VERSION "..\..\trunk\components\winTestMT\code\canApi\dbcFiles\canBus_08.dbc, created by Octave and generateRandomDbc.m on 21-Feb-2017"

NS_ :

BS_:

BU_: ECU

BO_ 1249 frame_1249: 5 Vector__XXX
  SG_ checksum_17_8 : 23|8@0+ (1.0,0.0) [0.0|255.0] "" ECU
  SG_ sig_0_16 : 0|16@1- (1.0000000000000007E-7,0.0031622776601683794) [-1.1452233983162306E-4|0.006438877660168382] "km/h" ECU
  SG_ sig_27_9 : 27|9@0- (1.0,0.0) [-256.0|254.0] "" ECU
  SG_ sig_28_6 : 28|6@1- (10.0,0.0) [-320.0|300.0] "km/h" ECU
  SG_ sig_34_1 : 34|1@0+ (1.0,0.0) [0.0|1.0] "" ECU

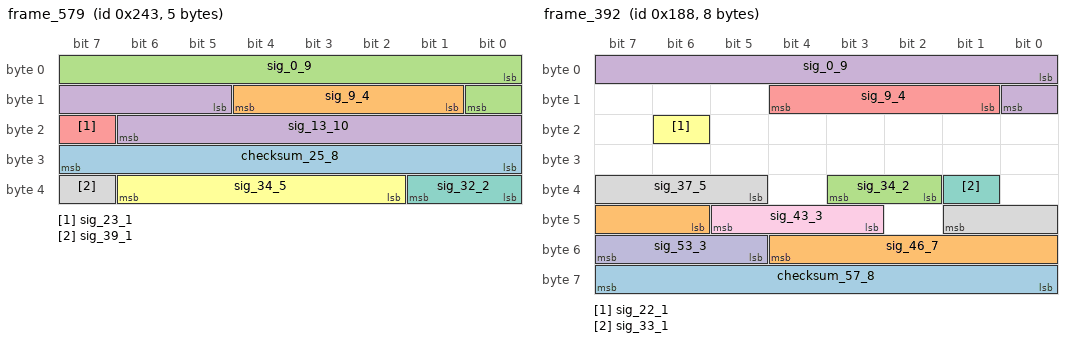
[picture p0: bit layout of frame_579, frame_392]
BO_ 579 frame_579: 5 Vector__XXX
  SG_ checksum_25_8 : 24|8@1+ (1.0,0.0) [0.0|255.0] "" ECU
  SG_ sig_9_4 : 9|4@1- (1.0,0.0) [-8.0|6.0] "" ECU
  SG_ sig_0_9 : 0|9@1+ (1.0,0.0) [0.0|510.0] "" ECU
  SG_ sig_13_10 : 13|10@1+ (1.0,0.0) [0.0|1022.0] "" ECU
  SG_ sig_23_1 : 23|1@1+ (1.0,0.0) [0.0|1.0] "" ECU
  SG_ sig_34_5 : 34|5@1- (0.0010000000000000002,-0.03162277660168379) [-0.04762277660168379|-0.017622776601683786] "W" ECU
  SG_ sig_32_2 : 32|2@1+ (1.0,0.0) [0.0|3.0] "" ECU
  SG_ sig_39_1 : 39|1@1+ (1.0,0.0) [0.0|1.0] "" ECU

BO_ 392 frame_392: 8 ECU
  SG_ checksum_57_8 : 56|8@1+ (1.0,0.0) [0.0|255.0] "" Vector__XXX
  SG_ sig_46_7 : 46|7@1+ (0.1,-3.1622776601683795) [-3.1622776601683795|9.437722339831621] "kWh" Vector__XXX
  SG_ sig_34_2 : 34|2@1+ (1.0,0.0) [0.0|3.0] "" Vector__XXX
  SG_ sig_0_9 : 0|9@1- (0.010000000000000002,3.1622776601683795) [0.602277660168379|5.70227766016838] "kWh" Vector__XXX
  SG_ sig_9_4 : 9|4@1- (0.1,-0.31622776601683794) [-1.116227766016838|0.28377223398316215] "kWh" Vector__XXX
  SG_ sig_22_1 : 22|1@1+ (1.0,0.0) [0.0|1.0] "" Vector__XXX
  SG_ sig_33_1 : 33|1@1+ (1.0,0.0) [0.0|1.0] "" Vector__XXX
  SG_ sig_37_5 : 37|5@1+ (0.010000000000000002,0.31622776601683794) [0.31622776601683794|0.616227766016838] "kWh" Vector__XXX
  SG_ sig_43_3 : 43|3@1- (1.0,0.0) [-4.0|2.0] "" Vector__XXX
  SG_ sig_53_3 : 53|3@1- (1.0,0.0) [-4.0|2.0] "" Vector__XXX

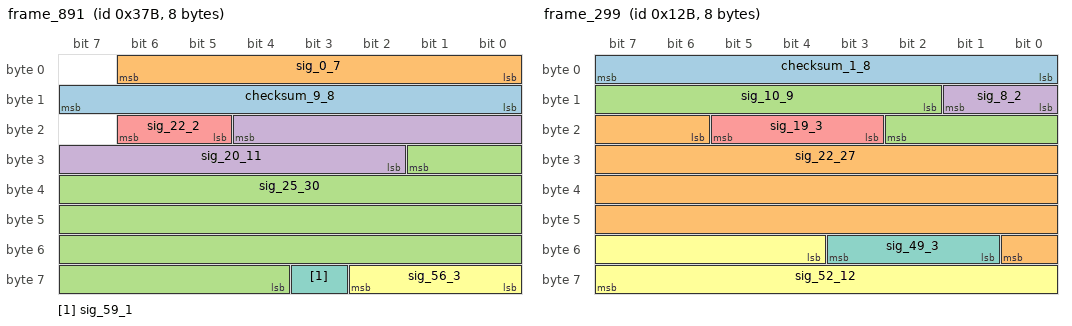
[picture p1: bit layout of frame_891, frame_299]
BO_ 891 frame_891: 8 Vector__XXX
  SG_ checksum_9_8 : 8|8@1+ (1.0,0.0) [0.0|255.0] "" ECU
  SG_ sig_0_7 : 0|7@1+ (10.0,0.0) [0.0|1260.0] "A" ECU
  SG_ sig_25_30 : 25|30@0+ (1.0000000000000014E-13,3.1622776601683795E-5) [3.1622776601683795E-5|1.3899695880168394E-4] "s" ECU
  SG_ sig_20_11 : 20|11@0- (1.0,0.0) [-1024.0|1022.0] "" ECU
  SG_ sig_22_2 : 22|2@0- (1.0,0.0) [-2.0|1.0] "" ECU
  SG_ sig_56_3 : 56|3@1+ (1.0,0.0) [0.0|6.0] "" ECU
  SG_ sig_59_1 : 59|1@0+ (1.0,0.0) [0.0|1.0] "" ECU

BO_ 1082 frame_1082: 6 Vector__XXX
  SG_ checksum_1_8 : 0|8@1+ (1.0,0.0) [0.0|255.0] "" ECU
  SG_ sig_38_12 : 38|12@0- (1.0,0.0) [-2048.0|2046.0] "" ECU
  SG_ sig_10_11 : 10|11@1- (10.0,0.0) [-10240.0|10220.0] "W" ECU
  SG_ sig_22_8 : 22|8@1+ (1.0,0.0) [0.0|254.0] "" ECU
  SG_ sig_39_4 : 39|4@1- (1.0,0.0) [-8.0|6.0] "V" ECU

BO_ 878 frame_878: 5 Vector__XXX
  SG_ checksum_17_8 : 23|8@0+ (1.0,0.0) [0.0|255.0] "" ECU
  SG_ sig_7_16 : 7|16@0+ (0.0010000000000000002,-31.622776601683793) [-31.622776601683793|33.911223398316224] "m/s^2" ECU
  SG_ sig_24_13 : 24|13@1- (1.0,0.0) [-4096.0|4094.0] "" ECU
  SG_ sig_39_2 : 39|2@0+ (1.0,0.0) [0.0|3.0] "" ECU

BO_ 299 frame_299: 8 Vector__XXX
  SG_ checksum_1_8 : 0|8@1+ (1.0,0.0) [0.0|255.0] "" ECU
  SG_ sig_22_27 : 22|27@1+ (1.0000000000000014E-12,3.1622776601683795E-5) [3.1622776601683795E-5|1.6584050260168398E-4] "V" ECU
  SG_ sig_10_9 : 10|9@1- (1.0,0.0) [-256.0|254.0] "" ECU
  SG_ sig_8_2 : 8|2@1+ (1.0,0.0) [0.0|3.0] "" ECU
  SG_ sig_19_3 : 19|3@1+ (1.0,0.0) [0.0|6.0] "" ECU
  SG_ sig_52_12 : 52|12@1+ (1.0,0.0) [0.0|4094.0] "" ECU
  SG_ sig_49_3 : 49|3@1- (1.0,0.0) [-4.0|2.0] "" ECU

BO_ 1921 frame_1921: 2 Vector__XXX
  SG_ checksum_1_8 : 0|8@1+ (1.0,0.0) [0.0|255.0] "" ECU
  SG_ sig_9_7 : 9|7@1+ (1.0,31.622776601683793) [31.622776601683793|157.6227766016838] "W" ECU
  SG_ sig_8_1 : 8|1@1+ (1.0,0.0) [0.0|1.0] "" ECU

BO_ 754 frame_754: 4 Vector__XXX
  SG_ checksum_9_8 : 15|8@0+ (1.0,0.0) [0.0|255.0] "" ECU
  SG_ sig_5_6 : 5|6@0- (1.0,0.0) [-32.0|30.0] "" ECU
  SG_ sig_7_2 : 7|2@0+ (1.0,0.0) [0.0|3.0] "" ECU
  SG_ sig_20_13 : 20|13@0- (10.0,-31622.776601683792) [-72582.77660168378|9317.223398316208] "s" ECU

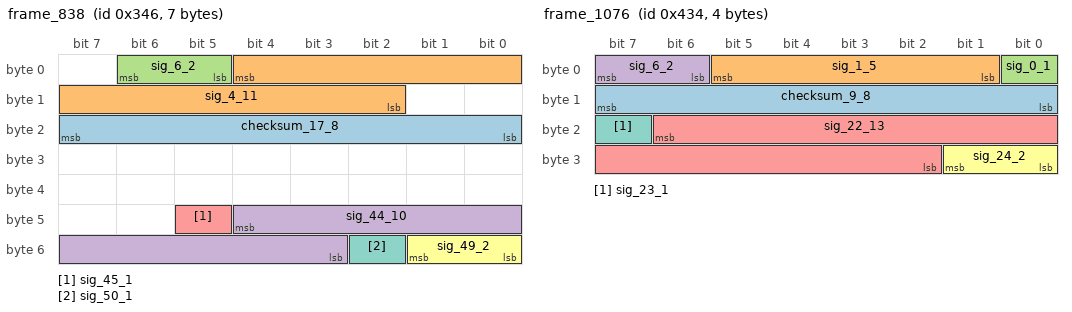
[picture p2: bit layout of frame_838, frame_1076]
BO_ 838 frame_838: 7 Vector__XXX
  SG_ checksum_17_8 : 23|8@0+ (1.0,0.0) [0.0|255.0] "" ECU
  SG_ sig_4_11 : 4|11@0+ (1.0000000000000008E-8,-3.162277660168379E-6) [-3.162277660168379E-6|1.729772233983164E-5] "A" ECU
  SG_ sig_6_2 : 6|2@0+ (1.0,0.0) [0.0|3.0] "" ECU
  SG_ sig_44_10 : 44|10@0- (1.0,0.0) [-512.0|510.0] "" ECU
  SG_ sig_45_1 : 45|1@0+ (1.0,0.0) [0.0|1.0] "" ECU
  SG_ sig_49_2 : 49|2@0- (1.0,0.0) [-2.0|1.0] "" ECU
  SG_ sig_50_1 : 50|1@0+ (1.0,0.0) [0.0|1.0] "" ECU

BO_ 33 frame_33: 4 ECU
  SG_ checksum_9_8 : 15|8@0+ (1.0,0.0) [0.0|255.0] "" Vector__XXX
  SG_ sig_7_8 : 7|8@0+ (1.0000000000000006E-5,0.0) [0.0|0.0025400000000000015] "km/h" Vector__XXX
  SG_ sig_21_11 : 21|11@0- (0.1,-31.622776601683793) [-134.0227766016838|70.5772233983162] "A" Vector__XXX
  SG_ sig_23_2 : 23|2@0- (1.0,0.0) [-2.0|1.0] "" Vector__XXX
  SG_ sig_26_3 : 26|3@0+ (1.0,0.0) [0.0|6.0] "" Vector__XXX

BO_ 1076 frame_1076: 4 ECU
  SG_ checksum_9_8 : 8|8@1+ (1.0,0.0) [0.0|255.0] "" Vector__XXX
  SG_ sig_1_5 : 1|5@1+ (1.0,0.0) [0.0|30.0] "" Vector__XXX
  SG_ sig_0_1 : 0|1@1+ (1.0,0.0) [0.0|1.0] "" Vector__XXX
  SG_ sig_6_2 : 6|2@1+ (1.0,0.0) [0.0|3.0] "" Vector__XXX
  SG_ sig_22_13 : 22|13@0+ (1.0,0.0) [0.0|8190.0] "" Vector__XXX
  SG_ sig_24_2 : 24|2@1+ (1.0,0.0) [0.0|3.0] "" Vector__XXX
  SG_ sig_23_1 : 23|1@1+ (1.0,0.0) [0.0|1.0] "" Vector__XXX

BO_ 16 frame_16: 7 Vector__XXX
  SG_ checksum_17_8 : 23|8@0+ (1.0,0.0) [0.0|255.0] "" ECU
  SG_ sig_0_13 : 0|13@1- (10.0,0.0) [-40960.0|40940.0] "s" ECU
  SG_ sig_13_3 : 13|3@1- (1.0,0.0) [-4.0|2.0] "" ECU
  SG_ sig_29_26 : 29|26@0+ (0.0010000000000000002,-31622.776601683792) [-31622.776601683792|35486.08539831623] "kWh" ECU
  SG_ sig_30_1 : 30|1@0+ (1.0,0.0) [0.0|1.0] "" ECU
  SG_ sig_51_4 : 51|4@0+ (10000.0,31622.776601683792) [31622.776601683792|171622.77660168378] "kWh" ECU

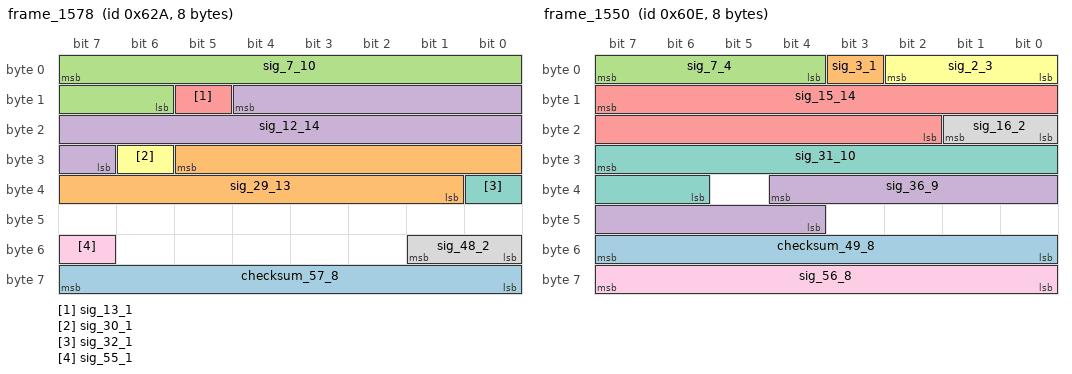
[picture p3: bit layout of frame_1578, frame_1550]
BO_ 1578 frame_1578: 8 Vector__XXX
  SG_ checksum_57_8 : 63|8@0+ (1.0,0.0) [0.0|255.0] "" ECU
  SG_ sig_29_13 : 29|13@0- (0.1,0.0) [-409.6|409.40000000000003] "A" ECU
  SG_ sig_7_10 : 7|10@0- (1.0,0.0) [-512.0|510.0] "" ECU
  SG_ sig_12_14 : 12|14@0+ (0.1,0.0) [0.0|1638.2] "W" ECU
  SG_ sig_13_1 : 13|1@0+ (1.0,0.0) [0.0|1.0] "" ECU
  SG_ sig_30_1 : 30|1@0+ (1.0,0.0) [0.0|1.0] "" ECU
  SG_ sig_32_1 : 32|1@1+ (1.0,0.0) [0.0|1.0] "" ECU
  SG_ sig_48_2 : 48|2@1+ (1.0,0.0) [0.0|3.0] "" ECU
  SG_ sig_55_1 : 55|1@0+ (1.0,0.0) [0.0|1.0] "" ECU

BO_ 1550 frame_1550: 8 Vector__XXX
  SG_ checksum_49_8 : 48|8@1+ (1.0,0.0) [0.0|255.0] "" ECU
  SG_ sig_3_1 : 3|1@1+ (1.0,0.0) [0.0|1.0] "" ECU
  SG_ sig_7_4 : 7|4@0+ (100.0,316.22776601683796) [316.22776601683796|1716.227766016838] "V" ECU
  SG_ sig_36_9 : 36|9@0- (1.0000000000000005E-4,0.03162277660168379) [0.00602277660168378|0.057022776601683804] "A" ECU
  SG_ sig_15_14 : 15|14@0- (1.0,0.0) [-8192.0|8190.0] "" ECU
  SG_ sig_2_3 : 2|3@0+ (1.0,0.0) [0.0|6.0] "" ECU
  SG_ sig_31_10 : 31|10@0- (0.0010000000000000002,0.0) [-0.5120000000000001|0.5100000000000001] "W" ECU
  SG_ sig_16_2 : 16|2@1- (1.0,0.0) [-2.0|1.0] "" ECU
  SG_ sig_56_8 : 56|8@1- (1.0,0.0) [-128.0|126.0] "" ECU

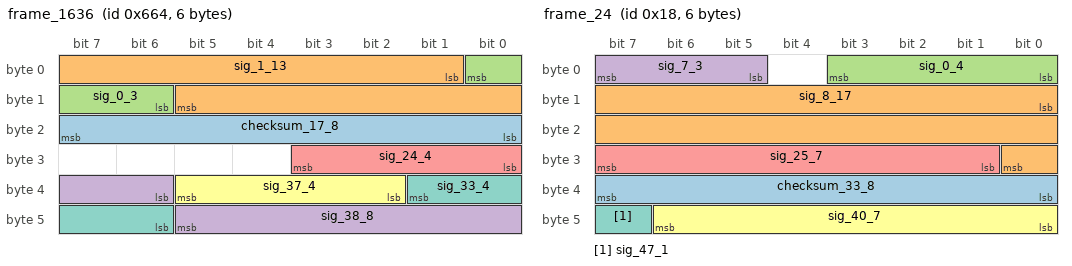
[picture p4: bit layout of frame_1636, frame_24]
BO_ 1636 frame_1636: 6 Vector__XXX
  SG_ checksum_17_8 : 23|8@0+ (1.0,0.0) [0.0|255.0] "" ECU
  SG_ sig_1_13 : 1|13@1- (1.0000000000000005E-4,-0.31622776601683794) [-0.7258277660168382|0.09317223398316227] "km/h" ECU
  SG_ sig_0_3 : 0|3@0+ (1.0,0.0) [0.0|6.0] "" ECU
  SG_ sig_38_8 : 38|8@1- (1000.0,0.0) [-128000.0|126000.0] "V" ECU
  SG_ sig_24_4 : 24|4@1- (1.0000000000000006E-6,3.162277660168379E-6) [-4.8377223398316255E-6|9.162277660168383E-6] "m/s^2" ECU
  SG_ sig_37_4 : 37|4@0+ (0.1,0.0) [0.0|1.4000000000000001] "W" ECU
  SG_ sig_33_4 : 33|4@0- (1.0,0.0) [-8.0|6.0] "" ECU

BO_ 24 frame_24: 6 ECU
  SG_ checksum_33_8 : 32|8@1+ (1.0,0.0) [0.0|255.0] "" Vector__XXX
  SG_ sig_8_17 : 8|17@1+ (1.0,0.0) [0.0|131070.0] "" Vector__XXX
  SG_ sig_0_4 : 0|4@1- (1.0,-3.1622776601683795) [-11.16227766016838|2.8377223398316205] "kWh" Vector__XXX
  SG_ sig_7_3 : 7|3@0+ (1.0,0.0) [0.0|6.0] "" Vector__XXX
  SG_ sig_25_7 : 25|7@1- (0.010000000000000002,-0.31622776601683794) [-0.9562277660168381|0.30377223398316217] "V" Vector__XXX
  SG_ sig_40_7 : 40|7@1+ (1.0,0.0) [0.0|126.0] "" Vector__XXX
  SG_ sig_47_1 : 47|1@1+ (1.0,0.0) [0.0|1.0] "" Vector__XXX

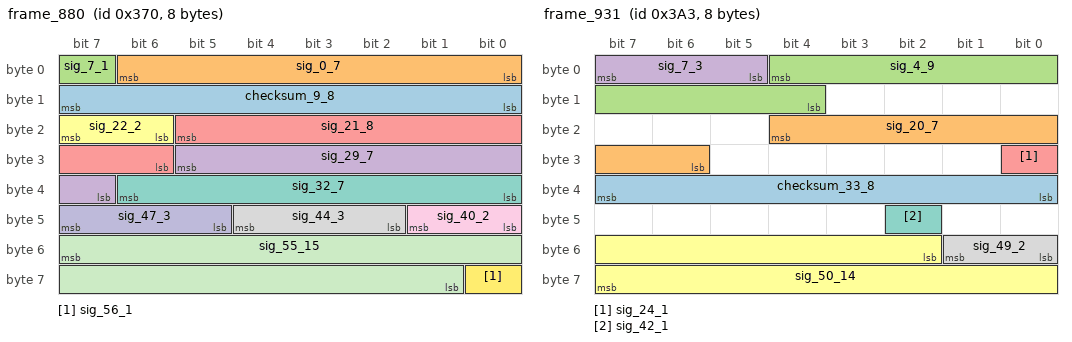
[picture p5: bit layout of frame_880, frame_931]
BO_ 880 frame_880: 8 ECU
  SG_ checksum_9_8 : 8|8@1+ (1.0,0.0) [0.0|255.0] "" Vector__XXX
  SG_ sig_0_7 : 0|7@1- (1.0,0.0) [-64.0|62.0] "" Vector__XXX
  SG_ sig_7_1 : 7|1@0+ (1.0,0.0) [0.0|1.0] "" Vector__XXX
  SG_ sig_29_7 : 29|7@0- (1.0,0.0) [-64.0|62.0] "" Vector__XXX
  SG_ sig_21_8 : 21|8@0- (100.0,0.0) [-12800.0|12600.0] "kWh" Vector__XXX
  SG_ sig_22_2 : 22|2@1- (1.0,0.0) [-2.0|1.0] "" Vector__XXX
  SG_ sig_32_7 : 32|7@1+ (0.0010000000000000002,0.0) [0.0|0.12600000000000003] "A" Vector__XXX
  SG_ sig_44_3 : 44|3@0- (1.0,0.0) [-4.0|2.0] "" Vector__XXX
  SG_ sig_40_2 : 40|2@1- (1.0,0.0) [-2.0|1.0] "" Vector__XXX
  SG_ sig_47_3 : 47|3@0+ (1.0,0.0) [0.0|6.0] "" Vector__XXX
  SG_ sig_55_15 : 55|15@0- (0.1,0.0) [-1638.4|1638.2] "m/s^2" Vector__XXX
  SG_ sig_56_1 : 56|1@0+ (1.0,0.0) [0.0|1.0] "" Vector__XXX

BO_ 575 frame_575: 4 Vector__XXX
  SG_ checksum_1_8 : 7|8@0+ (1.0,0.0) [0.0|255.0] "" ECU
  SG_ sig_8_8 : 8|8@0+ (1.0000000000000007E-7,3.162277660168379E-6) [3.162277660168379E-6|2.85622776601684E-5] "V" ECU
  SG_ sig_14_6 : 14|6@0- (1.0000000000000007E-7,3.162277660168379E-6) [-3.7722339831623205E-8|6.162277660168381E-6] "W" ECU
  SG_ sig_15_1 : 15|1@0+ (1.0,0.0) [0.0|1.0] "" ECU
  SG_ sig_16_6 : 16|6@0+ (0.0010000000000000002,0.0) [0.0|0.06200000000000001] "km/h" ECU
  SG_ sig_26_3 : 26|3@0- (1.0,0.0) [-4.0|2.0] "" ECU

BO_ 931 frame_931: 8 Vector__XXX
  SG_ checksum_33_8 : 39|8@0+ (1.0,0.0) [0.0|255.0] "" ECU
  SG_ sig_20_7 : 20|7@0- (10.0,316.22776601683796) [-323.77223398316204|936.2277660168379] "W" ECU
  SG_ sig_4_9 : 4|9@0+ (1.0,0.0) [0.0|510.0] "" ECU
  SG_ sig_7_3 : 7|3@0+ (1.0,0.0) [0.0|6.0] "" ECU
  SG_ sig_24_1 : 24|1@1+ (1.0,0.0) [0.0|1.0] "" ECU
  SG_ sig_50_14 : 50|14@1+ (1.0000000000000009E-9,3.162277660168379E-6) [3.162277660168379E-6|1.954427766016839E-5] "kWh" ECU
  SG_ sig_42_1 : 42|1@0+ (1.0,0.0) [0.0|1.0] "" ECU
  SG_ sig_49_2 : 49|2@0- (1.0,0.0) [-2.0|1.0] "" ECU

BO_ 525 frame_525: 7 Vector__XXX
  SG_ checksum_9_8 : 8|8@1+ (1.0,0.0) [0.0|255.0] "" ECU
  SG_ sig_0_8 : 0|8@1- (1.0000000000000006E-6,-3.1622776601683795E-5) [-1.5962277660168386E-4|9.437722339831629E-5] "kWh" ECU
  SG_ sig_42_1 : 42|1@1+ (1.0,0.0) [0.0|1.0] "" ECU
  SG_ sig_20_11 : 20|11@1- (1.0,0.0) [-1024.0|1022.0] "" ECU
  SG_ sig_17_3 : 17|3@1+ (1.0,0.0) [0.0|6.0] "" ECU
  SG_ sig_31_9 : 31|9@1+ (1.0000000000000008E-8,0.0) [0.0|5.1000000000000045E-6] "kWh" ECU
  SG_ sig_47_9 : 47|9@1- (1.0,0.0) [-256.0|254.0] "kWh" ECU

BO_ 1645 frame_1645: 3 Vector__XXX
  SG_ checksum_9_8 : 15|8@0+ (1.0,0.0) [0.0|255.0] "" ECU
  SG_ sig_5_6 : 5|6@0+ (100.0,0.0) [0.0|6200.0] "W" ECU
  SG_ sig_7_2 : 7|2@0+ (1.0,0.0) [0.0|3.0] "" ECU
  SG_ sig_23_8 : 23|8@0+ (100.0,3162.2776601683795) [3162.2776601683795|28562.27766016838] "W" ECU

BO_ 646 frame_646: 5 ECU
  SG_ checksum_17_8 : 23|8@0+ (1.0,0.0) [0.0|255.0] "" Vector__XXX
  SG_ sig_6_5 : 6|5@0+ (1.0,0.0) [0.0|30.0] "" Vector__XXX
  SG_ sig_0_2 : 0|2@1+ (1.0,0.0) [0.0|3.0] "" Vector__XXX
  SG_ sig_7_8 : 7|8@1- (1.0,0.0) [-128.0|126.0] "" Vector__XXX
  SG_ sig_15_1 : 15|1@0+ (1.0,0.0) [0.0|1.0] "" Vector__XXX
  SG_ sig_29_14 : 29|14@0- (1.0000000000000006E-5,0.0) [-0.08192000000000005|0.08190000000000004] "m/s^2" Vector__XXX
  SG_ sig_30_2 : 30|2@1+ (1.0,0.0) [0.0|3.0] "" Vector__XXX

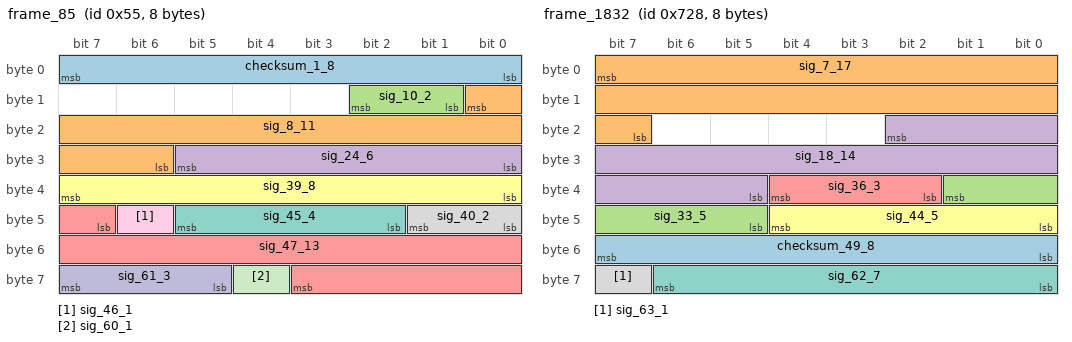
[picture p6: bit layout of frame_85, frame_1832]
BO_ 85 frame_85: 8 ECU
  SG_ checksum_1_8 : 0|8@1+ (1.0,0.0) [0.0|255.0] "" Vector__XXX
  SG_ sig_8_11 : 8|11@0- (1.0000000000000006E-6,-3.1622776601683794E-4) [-0.0013402277660168385|7.057722339831626E-4] "kWh" Vector__XXX
  SG_ sig_10_2 : 10|2@0+ (1.0,0.0) [0.0|3.0] "" Vector__XXX
  SG_ sig_24_6 : 24|6@1+ (1.0,31.622776601683793) [31.622776601683793|93.6227766016838] "V" Vector__XXX
  SG_ sig_47_13 : 47|13@1- (1.0,0.0) [-4096.0|4094.0] "" Vector__XXX
  SG_ sig_39_8 : 39|8@0- (0.010000000000000002,0.31622776601683794) [-0.9637722339831623|1.5762277660168382] "m/s^2" Vector__XXX
  SG_ sig_45_4 : 45|4@0- (10000.0,-31622.776601683792) [-111622.77660168378|28377.223398316208] "s" Vector__XXX
  SG_ sig_40_2 : 40|2@1- (1.0,0.0) [-2.0|1.0] "" Vector__XXX
  SG_ sig_46_1 : 46|1@0+ (1.0,0.0) [0.0|1.0] "" Vector__XXX
  SG_ sig_61_3 : 61|3@1- (1.0,0.0) [-4.0|2.0] "" Vector__XXX
  SG_ sig_60_1 : 60|1@1+ (1.0,0.0) [0.0|1.0] "" Vector__XXX

BO_ 1832 frame_1832: 8 Vector__XXX
  SG_ checksum_49_8 : 55|8@0+ (1.0,0.0) [0.0|255.0] "" ECU
  SG_ sig_7_17 : 7|17@0- (1.0,0.0) [-65536.0|65534.0] "" ECU
  SG_ sig_33_5 : 33|5@0- (1000.0,0.0) [-16000.0|14000.0] "m/s^2" ECU
  SG_ sig_18_14 : 18|14@0- (1.0000000000000009E-9,3.162277660168379E-6) [-5.029722339831628E-6|1.1352277660168387E-5] "km/h" ECU
  SG_ sig_36_3 : 36|3@0+ (1.0,0.0) [0.0|6.0] "" ECU
  SG_ sig_44_5 : 44|5@0- (1.0000000000000006E-6,3.1622776601683795E-5) [1.5622776601683786E-5|4.5622776601683804E-5] "km/h" ECU
  SG_ sig_62_7 : 62|7@0+ (0.010000000000000002,0.0) [0.0|1.2600000000000002] "m/s^2" ECU
  SG_ sig_63_1 : 63|1@0+ (1.0,0.0) [0.0|1.0] "" ECU

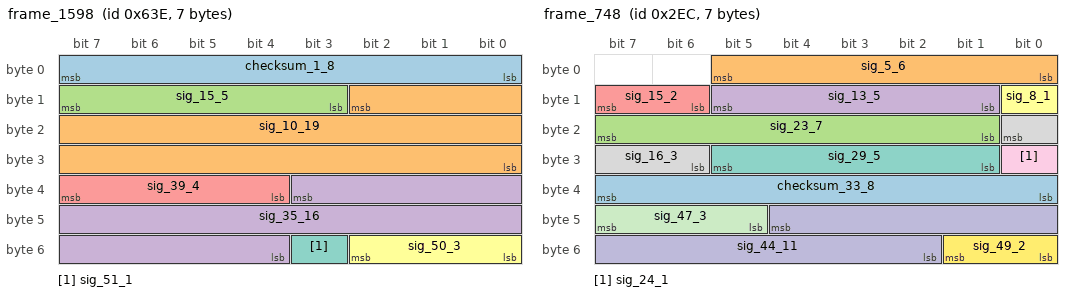
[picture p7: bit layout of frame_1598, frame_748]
BO_ 1598 frame_1598: 7 Vector__XXX
  SG_ checksum_1_8 : 7|8@0+ (1.0,0.0) [0.0|255.0] "" ECU
  SG_ sig_10_19 : 10|19@0+ (0.1,0.0) [0.0|52428.600000000006] "km/h" ECU
  SG_ sig_15_5 : 15|5@0- (10.0,-316.22776601683796) [-476.22776601683796|-176.22776601683796] "A" ECU
  SG_ sig_35_16 : 35|16@0- (1.0000000000000007E-7,0.0) [-0.0032768000000000025|0.0032766000000000023] "m/s^2" ECU
  SG_ sig_39_4 : 39|4@0- (1000.0,-3162.2776601683795) [-11162.27766016838|2837.7223398316205] "m/s^2" ECU
  SG_ sig_50_3 : 50|3@0+ (1.0,0.0) [0.0|6.0] "" ECU
  SG_ sig_51_1 : 51|1@0+ (1.0,0.0) [0.0|1.0] "" ECU

BO_ 696 frame_696: 3 ECU
  SG_ checksum_1_8 : 0|8@1+ (1.0,0.0) [0.0|255.0] "" Vector__XXX
  SG_ sig_11_13 : 11|13@1+ (1.0000000000000009E-9,-3.162277660168379E-6) [-3.162277660168379E-6|5.027722339831629E-6] "kWh" Vector__XXX
  SG_ sig_8_2 : 8|2@1- (1.0,0.0) [-2.0|1.0] "" Vector__XXX
  SG_ sig_10_1 : 10|1@1+ (1.0,0.0) [0.0|1.0] "" Vector__XXX

BO_ 1933 frame_1933: 5 Vector__XXX
  SG_ checksum_9_8 : 8|8@1+ (1.0,0.0) [0.0|255.0] "" ECU
  SG_ sig_1_6 : 1|6@1- (1.0000000000000007E-7,3.162277660168379E-6) [-3.7722339831623205E-8|6.162277660168381E-6] "A" ECU
  SG_ sig_7_1 : 7|1@1+ (1.0,0.0) [0.0|1.0] "" ECU
  SG_ sig_18_15 : 18|15@1- (1.0000000000000006E-5,0.0) [-0.1638400000000001|0.1638200000000001] "V" ECU
  SG_ sig_39_7 : 39|7@0+ (1.0,0.0) [0.0|126.0] "" ECU

BO_ 991 frame_991: 5 ECU
  SG_ checksum_1_8 : 0|8@1+ (1.0,0.0) [0.0|255.0] "" Vector__XXX
  SG_ sig_23_23 : 23|23@0+ (1.0000000000000005E-4,0.0) [0.0|838.8606000000004] "s" Vector__XXX
  SG_ sig_15_8 : 15|8@0- (1.0000000000000007E-7,3.162277660168379E-6) [-9.63772233983163E-6|1.576227766016839E-5] "m/s^2" Vector__XXX
  SG_ sig_32_1 : 32|1@1+ (1.0,0.0) [0.0|1.0] "" Vector__XXX

BO_ 1959 frame_1959: 3 Vector__XXX
  SG_ checksum_1_8 : 0|8@1+ (1.0,0.0) [0.0|255.0] "" ECU
  SG_ sig_8_16 : 8|16@1- (1.0,0.0) [-32768.0|32766.0] "" ECU

BO_ 748 frame_748: 7 Vector__XXX
  SG_ checksum_33_8 : 39|8@0+ (1.0,0.0) [0.0|255.0] "" ECU
  SG_ sig_5_6 : 5|6@0- (0.1,3.1622776601683795) [-0.037722339831620655|6.16227766016838] "kWh" ECU
  SG_ sig_23_7 : 23|7@0+ (1.0,0.0) [0.0|126.0] "" ECU
  SG_ sig_13_5 : 13|5@0+ (1.0,0.0) [0.0|30.0] "" ECU
  SG_ sig_15_2 : 15|2@0+ (1.0,0.0) [0.0|3.0] "" ECU
  SG_ sig_8_1 : 8|1@0+ (1.0,0.0) [0.0|1.0] "" ECU
  SG_ sig_29_5 : 29|5@0- (1.0,31.622776601683793) [15.622776601683793|45.622776601683796] "A" ECU
  SG_ sig_16_3 : 16|3@0+ (1.0,0.0) [0.0|6.0] "" ECU
  SG_ sig_24_1 : 24|1@0+ (1.0,0.0) [0.0|1.0] "" ECU
  SG_ sig_44_11 : 44|11@0+ (0.1,31.622776601683793) [31.622776601683793|236.22277660168382] "km/h" ECU
  SG_ sig_47_3 : 47|3@0- (1.0,0.0) [-4.0|2.0] "" ECU
  SG_ sig_49_2 : 49|2@0+ (1.0,0.0) [0.0|3.0] "" ECU

BO_ 1566 frame_1566: 5 Vector__XXX
  SG_ checksum_17_8 : 23|8@0+ (1.0,0.0) [0.0|255.0] "" ECU
  SG_ sig_2_12 : 2|12@1+ (1.0000000000000006E-6,0.0031622776601683794) [0.0031622776601683794|0.007256277660168382] "km/h" ECU
  SG_ sig_1_1 : 1|1@1+ (1.0,0.0) [0.0|1.0] "" ECU
  SG_ sig_0_3 : 0|3@0+ (1.0,0.0) [0.0|6.0] "" ECU
  SG_ sig_29_9 : 29|9@1- (0.0010000000000000002,0.0) [-0.25600000000000006|0.25400000000000006] "s" ECU
  SG_ sig_28_7 : 28|7@0- (1.0000000000000006E-5,3.1622776601683794E-4) [-3.2377223398316244E-4|9.362277660168383E-4] "V" ECU

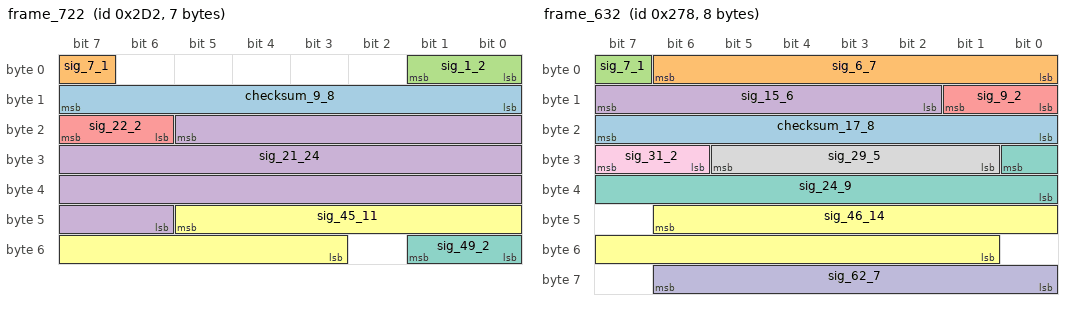
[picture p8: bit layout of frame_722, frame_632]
BO_ 722 frame_722: 7 Vector__XXX
  SG_ checksum_9_8 : 15|8@0+ (1.0,0.0) [0.0|255.0] "" ECU
  SG_ sig_7_1 : 7|1@0+ (1.0,0.0) [0.0|1.0] "" ECU
  SG_ sig_1_2 : 1|2@0- (1.0,0.0) [-2.0|1.0] "" ECU
  SG_ sig_21_24 : 21|24@0- (1.0000000000000011E-10,-3.1622776601683794E-4) [-0.0011550885660168387|5.22632833983163E-4] "A" ECU
  SG_ sig_22_2 : 22|2@1- (1.0,0.0) [-2.0|1.0] "" ECU
  SG_ sig_45_11 : 45|11@0+ (1.0,0.0) [0.0|2046.0] "" ECU
  SG_ sig_49_2 : 49|2@0+ (1.0,0.0) [0.0|3.0] "" ECU

BO_ 632 frame_632: 8 ECU
  SG_ checksum_17_8 : 23|8@0+ (1.0,0.0) [0.0|255.0] "" Vector__XXX
  SG_ sig_6_7 : 6|7@0+ (1000.0,-31622.776601683792) [-31622.776601683792|94377.22339831622] "m/s^2" Vector__XXX
  SG_ sig_7_1 : 7|1@0+ (1.0,0.0) [0.0|1.0] "" Vector__XXX
  SG_ sig_15_6 : 15|6@0- (1.0,0.0) [-32.0|30.0] "" Vector__XXX
  SG_ sig_9_2 : 9|2@0+ (1.0,0.0) [0.0|3.0] "" Vector__XXX
  SG_ sig_46_14 : 46|14@0+ (1.0000000000000005E-4,-0.31622776601683794) [-0.31622776601683794|1.3219722339831628] "A" Vector__XXX
  SG_ sig_24_9 : 24|9@0- (1.0,0.0) [-256.0|254.0] "" Vector__XXX
  SG_ sig_29_5 : 29|5@0- (1.0000000000000007E-7,3.162277660168379E-6) [1.562277660168378E-6|4.56227766016838E-6] "W" Vector__XXX
  SG_ sig_31_2 : 31|2@0+ (1.0,0.0) [0.0|3.0] "" Vector__XXX
  SG_ sig_62_7 : 62|7@0- (100.0,3162.2776601683795) [-3237.7223398316205|9362.27766016838] "km/h" Vector__XXX

BO_ 1388 frame_1388: 7 ECU
  SG_ checksum_1_8 : 7|8@0+ (1.0,0.0) [0.0|255.0] "" Vector__XXX
  SG_ sig_40_6 : 40|6@0- (0.010000000000000002,0.0) [-0.32000000000000006|0.30000000000000004] "s" Vector__XXX
  SG_ sig_14_15 : 14|15@0- (1.0000000000000007E-7,-0.0031622776601683794) [-0.004800677660168381|-0.001524077660168378] "km/h" Vector__XXX
  SG_ sig_15_1 : 15|1@0+ (1.0,0.0) [0.0|1.0] "" Vector__XXX
  SG_ sig_24_16 : 24|16@0+ (1.0,0.0) [0.0|65534.0] "" Vector__XXX
  SG_ sig_31_7 : 31|7@0+ (0.010000000000000002,0.31622776601683794) [0.31622776601683794|1.5762277660168382] "W" Vector__XXX
  SG_ sig_50_3 : 50|3@0- (1.0,0.0) [-4.0|2.0] "" Vector__XXX

BO_ 1817 frame_1817: 5 Vector__XXX
  SG_ checksum_9_8 : 15|8@0+ (1.0,0.0) [0.0|255.0] "" ECU
  SG_ sig_0_8 : 0|8@1- (1000.0,31622.776601683792) [-96377.22339831622|157622.77660168378] "V" ECU
  SG_ sig_22_21 : 22|21@0- (1.0000000000000009E-9,-3.1622776601683794E-4) [-0.0013648037660168389|7.32346233983163E-4] "W" ECU
  SG_ sig_23_1 : 23|1@0+ (1.0,0.0) [0.0|1.0] "" ECU
  SG_ sig_32_2 : 32|2@1+ (1.0,0.0) [0.0|3.0] "" ECU

BO_ 755 frame_755: 5 ECU
  SG_ checksum_25_8 : 31|8@0+ (1.0,0.0) [0.0|255.0] "" Vector__XXX
  SG_ sig_15_14 : 15|14@0- (1.0,0.0) [-8192.0|8190.0] "" Vector__XXX
  SG_ sig_0_8 : 0|8@1+ (1.0,-31.622776601683793) [-31.622776601683793|222.3772233983162] "km/h" Vector__XXX
  SG_ sig_17_1 : 17|1@0+ (1.0,0.0) [0.0|1.0] "" Vector__XXX
  SG_ sig_16_1 : 16|1@1+ (1.0,0.0) [0.0|1.0] "" Vector__XXX
  SG_ sig_36_4 : 36|4@1- (1.0,3.1622776601683795) [-4.83772233983162|9.16227766016838] "s" Vector__XXX
  SG_ sig_35_4 : 35|4@0+ (1.0000000000000006E-6,-3.162277660168379E-6) [-3.162277660168379E-6|1.0837722339831629E-5] "s" Vector__XXX

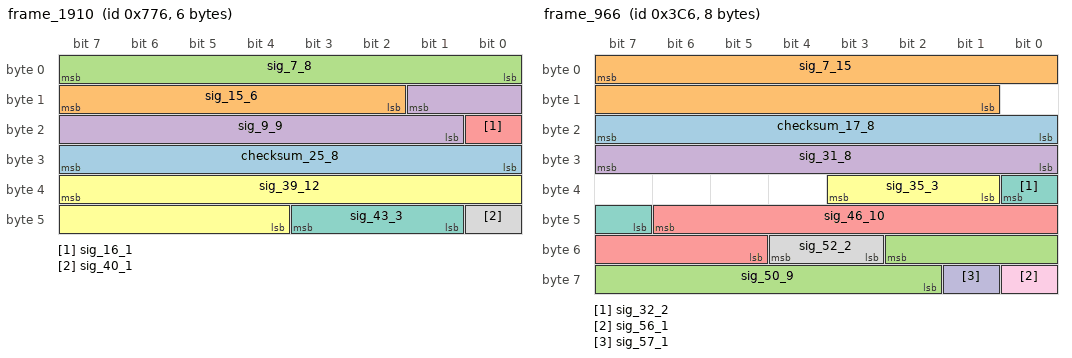
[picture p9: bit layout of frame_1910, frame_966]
BO_ 1910 frame_1910: 6 Vector__XXX
  SG_ checksum_25_8 : 31|8@0+ (1.0,0.0) [0.0|255.0] "" ECU
  SG_ sig_15_6 : 15|6@0- (1.0,0.0) [-32.0|30.0] "" ECU
  SG_ sig_7_8 : 7|8@0- (1.0,0.0) [-128.0|126.0] "" ECU
  SG_ sig_9_9 : 9|9@0+ (1.0000000000000006E-6,3.1622776601683794E-4) [3.1622776601683794E-4|8.262277660168382E-4] "W" ECU
  SG_ sig_16_1 : 16|1@0+ (1.0,0.0) [0.0|1.0] "" ECU
  SG_ sig_39_12 : 39|12@0- (1.0000000000000009E-9,-3.162277660168379E-6) [-5.210277660168381E-6|-1.1162776601683775E-6] "km/h" ECU
  SG_ sig_43_3 : 43|3@0- (1.0,0.0) [-4.0|2.0] "" ECU
  SG_ sig_40_1 : 40|1@0+ (1.0,0.0) [0.0|1.0] "" ECU

BO_ 966 frame_966: 8 ECU
  SG_ checksum_17_8 : 23|8@0+ (1.0,0.0) [0.0|255.0] "" Vector__XXX
  SG_ sig_7_15 : 7|15@0- (0.010000000000000002,0.0) [-163.84000000000003|163.82000000000002] "A" Vector__XXX
  SG_ sig_50_9 : 50|9@0+ (1.0,0.0) [0.0|510.0] "" Vector__XXX
  SG_ sig_31_8 : 31|8@0- (1.0,0.0) [-128.0|126.0] "" Vector__XXX
  SG_ sig_46_10 : 46|10@0- (1.0000000000000006E-6,3.1622776601683794E-4) [-1.9577223398316236E-4|8.262277660168382E-4] "s" Vector__XXX
  SG_ sig_35_3 : 35|3@0+ (1.0,0.0) [0.0|6.0] "" Vector__XXX
  SG_ sig_32_2 : 32|2@0- (1.0,0.0) [-2.0|1.0] "" Vector__XXX
  SG_ sig_52_2 : 52|2@0+ (1.0,0.0) [0.0|3.0] "" Vector__XXX
  SG_ sig_56_1 : 56|1@0+ (1.0,0.0) [0.0|1.0] "" Vector__XXX
  SG_ sig_57_1 : 57|1@0+ (1.0,0.0) [0.0|1.0] "" Vector__XXX

BO_ 75 frame_75: 7 Vector__XXX
  SG_ checksum_49_8 : 48|8@1+ (1.0,0.0) [0.0|255.0] "" ECU
  SG_ sig_21_19 : 21|19@1+ (1.0,0.0) [0.0|524286.0] "" ECU
  SG_ sig_0_18 : 0|18@1- (1.0,0.0) [-131072.0|131070.0] "" ECU
  SG_ sig_42_6 : 42|6@1- (1.0,0.0) [-32.0|30.0] "" ECU
  SG_ sig_40_2 : 40|2@1+ (1.0,0.0) [0.0|3.0] "" ECU

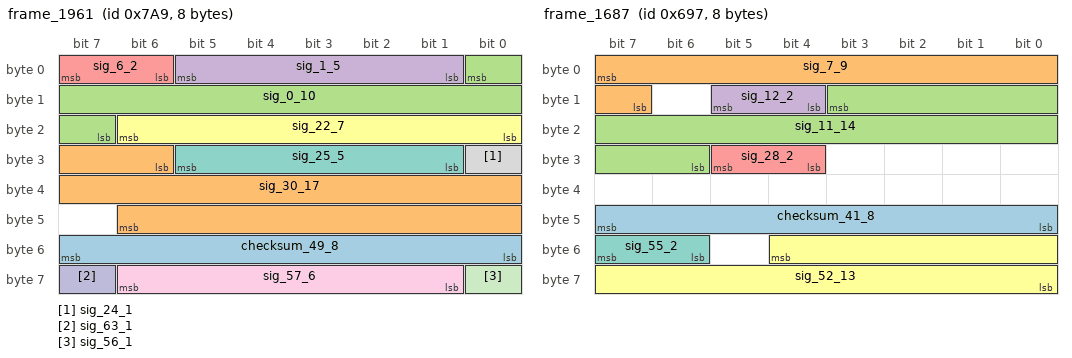
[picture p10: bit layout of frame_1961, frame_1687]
BO_ 1961 frame_1961: 8 ECU
  SG_ checksum_49_8 : 55|8@0+ (1.0,0.0) [0.0|255.0] "" Vector__XXX
  SG_ sig_30_17 : 30|17@1+ (1.0000000000000009E-9,3.1622776601683795E-5) [3.1622776601683795E-5|1.626927766016839E-4] "W" Vector__XXX
  SG_ sig_0_10 : 0|10@0+ (0.1,31.622776601683793) [31.622776601683793|133.82277660168378] "V" Vector__XXX
  SG_ sig_1_5 : 1|5@1- (1.0,0.0) [-16.0|14.0] "" Vector__XXX
  SG_ sig_6_2 : 6|2@1- (1.0,0.0) [-2.0|1.0] "" Vector__XXX
  SG_ sig_22_7 : 22|7@0+ (10.0,-316.22776601683796) [-316.22776601683796|943.7722339831621] "A" Vector__XXX
  SG_ sig_25_5 : 25|5@1- (1.0000000000000007E-7,3.162277660168379E-6) [1.562277660168378E-6|4.56227766016838E-6] "s" Vector__XXX
  SG_ sig_24_1 : 24|1@1+ (1.0,0.0) [0.0|1.0] "" Vector__XXX
  SG_ sig_57_6 : 57|6@1- (0.010000000000000002,0.31622776601683794) [-0.003772233983162121|0.616227766016838] "W" Vector__XXX
  SG_ sig_63_1 : 63|1@0+ (1.0,0.0) [0.0|1.0] "" Vector__XXX
  SG_ sig_56_1 : 56|1@0+ (1.0,0.0) [0.0|1.0] "" Vector__XXX

BO_ 1687 frame_1687: 8 ECU
  SG_ checksum_41_8 : 40|8@1+ (1.0,0.0) [0.0|255.0] "" Vector__XXX
  SG_ sig_7_9 : 7|9@0+ (1.0,316.22776601683796) [316.22776601683796|826.2277660168379] "kWh" Vector__XXX
  SG_ sig_11_14 : 11|14@0+ (1.0,0.0) [0.0|16382.0] "" Vector__XXX
  SG_ sig_12_2 : 12|2@1- (1.0,0.0) [-2.0|1.0] "" Vector__XXX
  SG_ sig_28_2 : 28|2@1- (1.0,0.0) [-2.0|1.0] "" Vector__XXX
  SG_ sig_52_13 : 52|13@0+ (1.0000000000000008E-8,3.1622776601683795E-5) [3.1622776601683795E-5|1.1352277660168385E-4] "m/s^2" Vector__XXX
  SG_ sig_55_2 : 55|2@0+ (1.0,0.0) [0.0|3.0] "" Vector__XXX

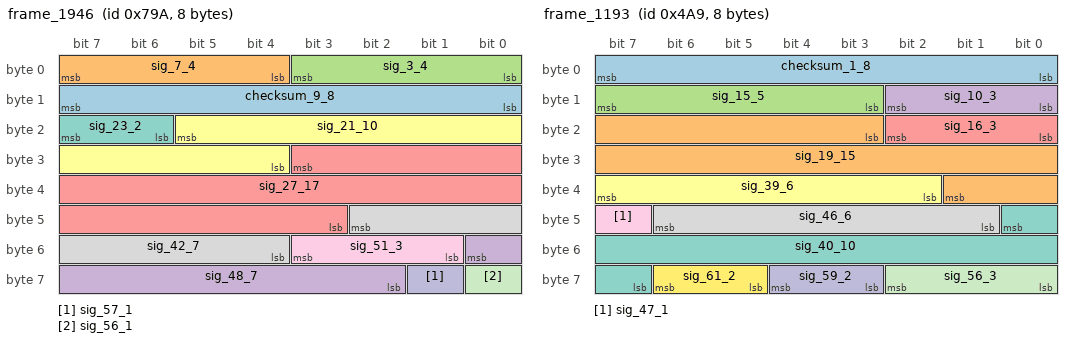
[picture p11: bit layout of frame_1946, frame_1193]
BO_ 1946 frame_1946: 8 Vector__XXX
  SG_ checksum_9_8 : 15|8@0+ (1.0,0.0) [0.0|255.0] "" ECU
  SG_ sig_7_4 : 7|4@0- (0.0010000000000000002,-0.0031622776601683794) [-0.011162277660168382|0.0028377223398316225] "W" ECU
  SG_ sig_3_4 : 3|4@0- (1.0,0.0) [-8.0|6.0] "" ECU
  SG_ sig_48_7 : 48|7@0- (1.0000000000000006E-6,0.0) [-6.400000000000004E-5|6.200000000000004E-5] "m/s^2" ECU
  SG_ sig_27_17 : 27|17@0- (1.0000000000000007E-7,0.0) [-0.006553600000000005|0.006553400000000005] "W" ECU
  SG_ sig_21_10 : 21|10@0+ (1.0,-316.22776601683796) [-316.22776601683796|705.7722339831621] "km/h" ECU
  SG_ sig_23_2 : 23|2@0- (1.0,0.0) [-2.0|1.0] "" ECU
  SG_ sig_42_7 : 42|7@0- (1.0,0.0) [-64.0|62.0] "" ECU
  SG_ sig_51_3 : 51|3@0+ (1.0,0.0) [0.0|6.0] "" ECU
  SG_ sig_57_1 : 57|1@0+ (1.0,0.0) [0.0|1.0] "" ECU
  SG_ sig_56_1 : 56|1@0+ (1.0,0.0) [0.0|1.0] "" ECU

BO_ 1663 frame_1663: 4 ECU
  SG_ checksum_1_8 : 7|8@0+ (1.0,0.0) [0.0|255.0] "" Vector__XXX
  SG_ sig_12_16 : 12|16@1+ (1.0,0.0) [0.0|65534.0] "" Vector__XXX
  SG_ sig_8_4 : 8|4@1- (1.0000000000000005E-4,-3.1622776601683794E-4) [-0.0011162277660168383|2.8377223398316233E-4] "s" Vector__XXX
  SG_ sig_31_4 : 31|4@0- (1.0000000000000005E-4,0.0) [-8.000000000000004E-4|6.000000000000003E-4] "W" Vector__XXX

BO_ 1193 frame_1193: 8 Vector__XXX
  SG_ checksum_1_8 : 0|8@1+ (1.0,0.0) [0.0|255.0] "" ECU
  SG_ sig_19_15 : 19|15@1- (1.0000000000000011E-10,-3.162277660168379E-6) [-4.800677660168381E-6|-1.5240776601683775E-6] "m/s^2" ECU
  SG_ sig_15_5 : 15|5@0- (100.0,3162.2776601683795) [1562.2776601683795|4562.27766016838] "kWh" ECU
  SG_ sig_10_3 : 10|3@0+ (1.0,0.0) [0.0|6.0] "" ECU
  SG_ sig_16_3 : 16|3@1- (1.0,0.0) [-4.0|2.0] "" ECU
  SG_ sig_39_6 : 39|6@0+ (1.0,0.0) [0.0|62.0] "" ECU
  SG_ sig_40_10 : 40|10@0+ (1.0,316.22776601683796) [316.22776601683796|1338.227766016838] "A" ECU
  SG_ sig_46_6 : 46|6@0+ (1.0,0.0) [0.0|62.0] "" ECU
  SG_ sig_47_1 : 47|1@1+ (1.0,0.0) [0.0|1.0] "" ECU
  SG_ sig_59_2 : 59|2@1- (1.0,0.0) [-2.0|1.0] "" ECU
  SG_ sig_56_3 : 56|3@1+ (1.0,0.0) [0.0|6.0] "" ECU
  SG_ sig_61_2 : 61|2@1+ (1.0,0.0) [0.0|3.0] "" ECU

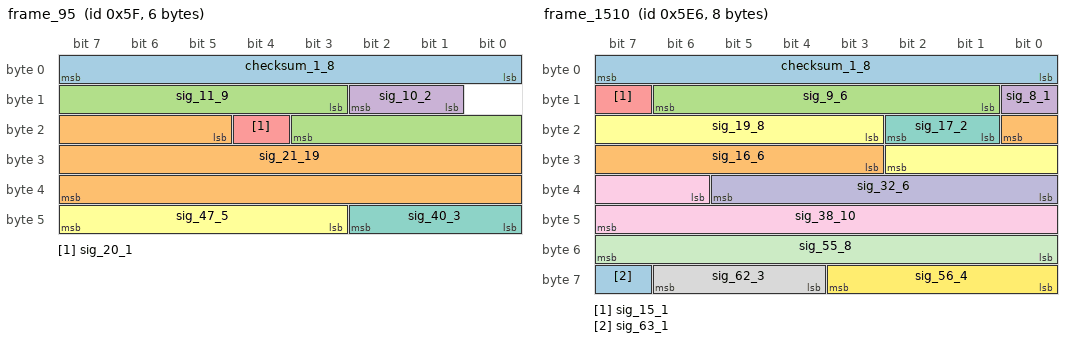
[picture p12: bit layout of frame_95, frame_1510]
BO_ 95 frame_95: 6 Vector__XXX
  SG_ checksum_1_8 : 7|8@0+ (1.0,0.0) [0.0|255.0] "" ECU
  SG_ sig_21_19 : 21|19@1+ (0.010000000000000002,3162.2776601683795) [3162.2776601683795|8405.13766016838] "s" ECU
  SG_ sig_11_9 : 11|9@1- (1.0000000000000008E-8,3.162277660168379E-6) [6.02277660168377E-7|5.702277660168382E-6] "m/s^2" ECU
  SG_ sig_10_2 : 10|2@0- (1.0,0.0) [-2.0|1.0] "" ECU
  SG_ sig_20_1 : 20|1@0+ (1.0,0.0) [0.0|1.0] "" ECU
  SG_ sig_47_5 : 47|5@0- (1000.0,0.0) [-16000.0|14000.0] "km/h" ECU
  SG_ sig_40_3 : 40|3@1- (1.0,0.0) [-4.0|2.0] "" ECU

BO_ 1510 frame_1510: 8 ECU
  SG_ checksum_1_8 : 0|8@1+ (1.0,0.0) [0.0|255.0] "" Vector__XXX
  SG_ sig_16_6 : 16|6@0+ (1.0000000000000005E-4,-0.0031622776601683794) [-0.0031622776601683794|0.003037722339831623] "kWh" Vector__XXX
  SG_ sig_9_6 : 9|6@1- (1.0,0.0) [-32.0|30.0] "" Vector__XXX
  SG_ sig_8_1 : 8|1@1+ (1.0,0.0) [0.0|1.0] "" Vector__XXX
  SG_ sig_15_1 : 15|1@1+ (1.0,0.0) [0.0|1.0] "" Vector__XXX
  SG_ sig_19_8 : 19|8@1- (1.0000000000000005E-4,0.0) [-0.012800000000000006|0.012600000000000005] "A" Vector__XXX
  SG_ sig_17_2 : 17|2@1+ (1.0,0.0) [0.0|3.0] "" Vector__XXX
  SG_ sig_62_3 : 62|3@0- (1.0,0.0) [-4.0|2.0] "" Vector__XXX
  SG_ sig_38_10 : 38|10@1+ (1.0,0.0) [0.0|1022.0] "" Vector__XXX
  SG_ sig_32_6 : 32|6@1- (100.0,-3162.2776601683795) [-6362.27766016838|-162.2776601683795] "km/h" Vector__XXX
  SG_ sig_55_8 : 55|8@0+ (1.0,0.0) [0.0|254.0] "" Vector__XXX
  SG_ sig_56_4 : 56|4@1+ (10.0,-31.622776601683793) [-31.622776601683793|108.3772233983162] "km/h" Vector__XXX
  SG_ sig_63_1 : 63|1@0+ (1.0,0.0) [0.0|1.0] "" Vector__XXX

BO_ 1678 frame_1678: 6 Vector__XXX
  SG_ checksum_25_8 : 24|8@1+ (1.0,0.0) [0.0|255.0] "" ECU
  SG_ sig_0_15 : 0|15@1- (1.0,0.0) [-16384.0|16382.0] "" ECU
  SG_ sig_15_8 : 15|8@1- (1.0,0.0) [-128.0|126.0] "" ECU
  SG_ sig_34_13 : 34|13@1+ (1.0,3162.2776601683795) [3162.2776601683795|11352.27766016838] "V" ECU
  SG_ sig_32_2 : 32|2@1+ (1.0,0.0) [0.0|3.0] "" ECU
  SG_ sig_47_1 : 47|1@1+ (1.0,0.0) [0.0|1.0] "" ECU

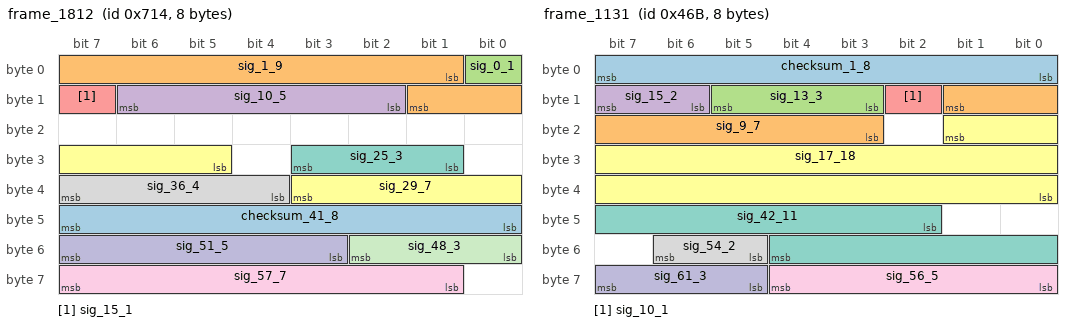
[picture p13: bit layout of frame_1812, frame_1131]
BO_ 1812 frame_1812: 8 Vector__XXX
  SG_ checksum_41_8 : 40|8@1+ (1.0,0.0) [0.0|255.0] "" ECU
  SG_ sig_1_9 : 1|9@1- (0.1,0.0) [-25.6|25.400000000000002] "s" ECU
  SG_ sig_0_1 : 0|1@1+ (1.0,0.0) [0.0|1.0] "" ECU
  SG_ sig_10_5 : 10|5@1- (1.0,0.0) [-16.0|14.0] "" ECU
  SG_ sig_15_1 : 15|1@1+ (1.0,0.0) [0.0|1.0] "" ECU
  SG_ sig_29_7 : 29|7@1- (1.0,0.0) [-64.0|62.0] "" ECU
  SG_ sig_25_3 : 25|3@1- (1.0,0.0) [-4.0|2.0] "" ECU
  SG_ sig_36_4 : 36|4@1+ (0.0010000000000000002,0.0031622776601683794) [0.0031622776601683794|0.017162277660168382] "m/s^2" ECU
  SG_ sig_57_7 : 57|7@1+ (1.0,0.0) [0.0|126.0] "" ECU
  SG_ sig_51_5 : 51|5@1+ (1.0,-31.622776601683793) [-31.622776601683793|-1.6227766016837926] "kWh" ECU
  SG_ sig_48_3 : 48|3@1- (1.0,0.0) [-4.0|2.0] "" ECU

BO_ 1131 frame_1131: 8 Vector__XXX
  SG_ checksum_1_8 : 0|8@1+ (1.0,0.0) [0.0|255.0] "" ECU
  SG_ sig_9_7 : 9|7@0+ (0.010000000000000002,0.0) [0.0|1.2600000000000002] "km/h" ECU
  SG_ sig_13_3 : 13|3@0+ (1.0,0.0) [0.0|6.0] "" ECU
  SG_ sig_15_2 : 15|2@0+ (1.0,0.0) [0.0|3.0] "" ECU
  SG_ sig_10_1 : 10|1@1+ (1.0,0.0) [0.0|1.0] "" ECU
  SG_ sig_17_18 : 17|18@0- (0.1,3162.2776601683795) [-9944.92233983162|16269.27766016838] "m/s^2" ECU
  SG_ sig_42_11 : 42|11@1+ (1.0,0.0) [0.0|2046.0] "" ECU
  SG_ sig_54_2 : 54|2@0+ (1.0,0.0) [0.0|3.0] "" ECU
  SG_ sig_56_5 : 56|5@1- (1.0000000000000007E-7,0.0) [-1.6000000000000012E-6|1.400000000000001E-6] "m/s^2" ECU
  SG_ sig_61_3 : 61|3@1+ (1.0,0.0) [0.0|6.0] "" ECU

BO_ 625 frame_625: 5 Vector__XXX
  SG_ checksum_1_8 : 0|8@1+ (1.0,0.0) [0.0|255.0] "" ECU
  SG_ sig_8_13 : 8|13@1+ (0.1,0.0) [0.0|819.0] "km/h" ECU
  SG_ sig_25_7 : 25|7@1+ (1.0,0.0) [0.0|126.0] "" ECU
  SG_ sig_21_4 : 21|4@1- (0.0010000000000000002,0.0031622776601683794) [-0.004837722339831622|0.009162277660168382] "m/s^2" ECU
  SG_ sig_38_2 : 38|2@1+ (1.0,0.0) [0.0|3.0] "" ECU
  SG_ sig_32_5 : 32|5@1+ (0.1,3.1622776601683795) [3.1622776601683795|6.16227766016838] "V" ECU

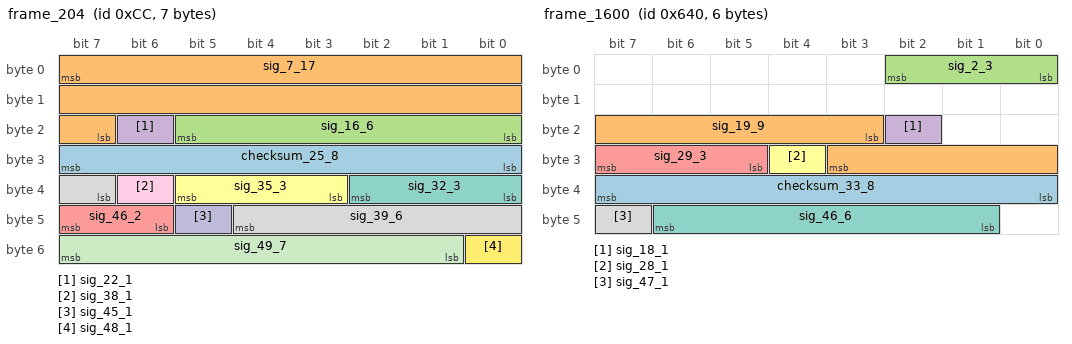
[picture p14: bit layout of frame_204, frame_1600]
BO_ 204 frame_204: 7 Vector__XXX
  SG_ checksum_25_8 : 24|8@1+ (1.0,0.0) [0.0|255.0] "" ECU
  SG_ sig_7_17 : 7|17@0+ (1.0,0.0) [0.0|131070.0] "" ECU
  SG_ sig_16_6 : 16|6@1- (0.0010000000000000002,-0.03162277660168379) [-0.0636227766016838|-0.0016227766016837855] "s" ECU
  SG_ sig_22_1 : 22|1@0+ (1.0,0.0) [0.0|1.0] "" ECU
  SG_ sig_46_2 : 46|2@1+ (1.0,0.0) [0.0|3.0] "" ECU
  SG_ sig_35_3 : 35|3@1+ (1.0,0.0) [0.0|6.0] "" ECU
  SG_ sig_32_3 : 32|3@1+ (1.0,0.0) [0.0|6.0] "" ECU
  SG_ sig_39_6 : 39|6@1+ (1.0,31.622776601683793) [31.622776601683793|93.6227766016838] "A" ECU
  SG_ sig_38_1 : 38|1@0+ (1.0,0.0) [0.0|1.0] "" ECU
  SG_ sig_45_1 : 45|1@0+ (1.0,0.0) [0.0|1.0] "" ECU
  SG_ sig_49_7 : 49|7@1- (1.0,0.0) [-64.0|62.0] "" ECU
  SG_ sig_48_1 : 48|1@0+ (1.0,0.0) [0.0|1.0] "" ECU

BO_ 1700 frame_1700: 8 Vector__XXX
  SG_ checksum_1_8 : 0|8@1+ (1.0,0.0) [0.0|255.0] "" ECU
  SG_ sig_28_28 : 28|28@1+ (1.0000000000000014E-12,-3.1622776601683795E-5) [-3.1622776601683795E-5|2.368126773983166E-4] "km/h" ECU
  SG_ sig_14_12 : 14|12@1- (0.1,-316.22776601683796) [-521.027766016838|-111.62776601683794] "V" ECU
  SG_ sig_11_3 : 11|3@1+ (1.0,0.0) [0.0|6.0] "" ECU
  SG_ sig_8_3 : 8|3@1- (1.0,0.0) [-4.0|2.0] "" ECU
  SG_ sig_56_4 : 56|4@1+ (10.0,-31.622776601683793) [-31.622776601683793|108.3772233983162] "A" ECU
  SG_ sig_60_4 : 60|4@1+ (1.0000000000000006E-6,-3.162277660168379E-6) [-3.162277660168379E-6|1.0837722339831629E-5] "s" ECU

BO_ 1460 frame_1460: 4 ECU
  SG_ checksum_9_8 : 8|8@1+ (1.0,0.0) [0.0|255.0] "" Vector__XXX
  SG_ sig_3_5 : 3|5@1- (100.0,0.0) [-1600.0|1400.0] "W" Vector__XXX
  SG_ sig_0_3 : 0|3@1+ (1.0,0.0) [0.0|6.0] "" Vector__XXX
  SG_ sig_16_15 : 16|15@1- (1.0,0.0) [-16384.0|16382.0] "" Vector__XXX
  SG_ sig_31_1 : 31|1@1+ (1.0,0.0) [0.0|1.0] "" Vector__XXX

BO_ 1600 frame_1600: 6 Vector__XXX
  SG_ checksum_33_8 : 32|8@1+ (1.0,0.0) [0.0|255.0] "" ECU
  SG_ sig_19_9 : 19|9@1+ (0.1,-31.622776601683793) [-31.622776601683793|19.377223398316207] "kWh" ECU
  SG_ sig_2_3 : 2|3@0- (1.0,0.0) [-4.0|2.0] "" ECU
  SG_ sig_18_1 : 18|1@0+ (1.0,0.0) [0.0|1.0] "" ECU
  SG_ sig_29_3 : 29|3@1- (1.0,0.0) [-4.0|2.0] "" ECU
  SG_ sig_28_1 : 28|1@0+ (1.0,0.0) [0.0|1.0] "" ECU
  SG_ sig_46_6 : 46|6@0- (1.0000000000000005E-4,-0.0031622776601683794) [-0.006362277660168381|-1.6227766016837803E-4] "W" ECU
  SG_ sig_47_1 : 47|1@0+ (1.0,0.0) [0.0|1.0] "" ECU

BO_ 653 frame_653: 7 ECU
  SG_ checksum_17_8 : 23|8@0+ (1.0,0.0) [0.0|255.0] "" Vector__XXX
  SG_ sig_3_11 : 3|11@0+ (1.0,316.22776601683796) [316.22776601683796|2362.227766016838] "W" Vector__XXX
  SG_ sig_4_2 : 4|2@1+ (1.0,0.0) [0.0|3.0] "" Vector__XXX
  SG_ sig_41_8 : 41|8@0- (1000.0,0.0) [-128000.0|126000.0] "km/h" Vector__XXX
  SG_ sig_31_7 : 31|7@1+ (1.0,-31.622776601683793) [-31.622776601683793|94.3772233983162] "kWh" Vector__XXX
  SG_ sig_24_7 : 24|7@1+ (1.0000000000000006E-5,0.0) [0.0|0.0012600000000000007] "V" Vector__XXX
  SG_ sig_42_8 : 42|8@1- (1.0,0.0) [-128.0|126.0] "" Vector__XXX

BO_ 699 frame_699: 4 ECU
  SG_ checksum_9_8 : 8|8@1+ (1.0,0.0) [0.0|255.0] "" Vector__XXX
  SG_ sig_0_8 : 0|8@1- (1.0000000000000006E-6,0.0) [-1.2800000000000008E-4|1.2600000000000008E-4] "s" Vector__XXX
  SG_ sig_16_16 : 16|16@1- (1.0000000000000007E-7,0.0031622776601683794) [-1.1452233983162306E-4|0.006438877660168382] "W" Vector__XXX

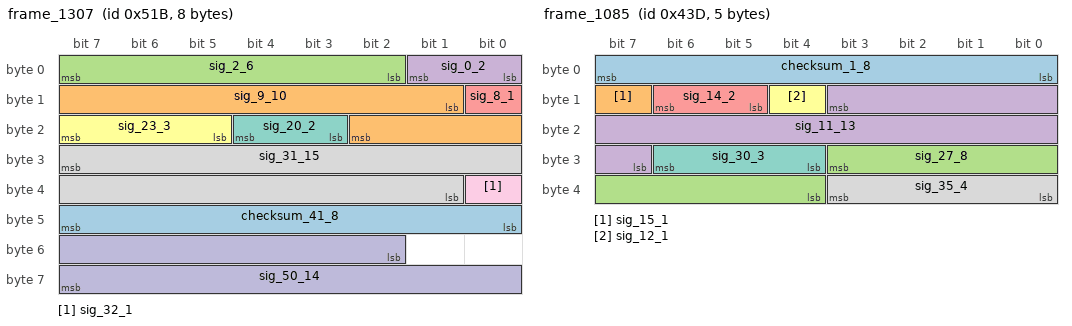
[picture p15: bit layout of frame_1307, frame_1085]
BO_ 1307 frame_1307: 8 Vector__XXX
  SG_ checksum_41_8 : 47|8@0+ (1.0,0.0) [0.0|255.0] "" ECU
  SG_ sig_9_10 : 9|10@1+ (1.0,0.0) [0.0|1022.0] "" ECU
  SG_ sig_2_6 : 2|6@1- (1.0000000000000005E-4,0.0031622776601683794) [-3.772233983162206E-5|0.006162277660168381] "km/h" ECU
  SG_ sig_0_2 : 0|2@1- (1.0,0.0) [-2.0|1.0] "" ECU
  SG_ sig_8_1 : 8|1@1+ (1.0,0.0) [0.0|1.0] "" ECU
  SG_ sig_23_3 : 23|3@0- (1.0,0.0) [-4.0|2.0] "" ECU
  SG_ sig_20_2 : 20|2@0+ (1.0,0.0) [0.0|3.0] "" ECU
  SG_ sig_31_15 : 31|15@0- (1.0000000000000005E-4,-3.1622776601683795) [-4.800677660168381|-1.5240776601683788] "A" ECU
  SG_ sig_32_1 : 32|1@0+ (1.0,0.0) [0.0|1.0] "" ECU
  SG_ sig_50_14 : 50|14@1+ (1.0,0.0) [0.0|16382.0] "" ECU

BO_ 1414 frame_1414: 7 Vector__XXX
  SG_ checksum_1_8 : 0|8@1+ (1.0,0.0) [0.0|255.0] "" ECU
  SG_ sig_11_30 : 11|30@0+ (1.0000000000000014E-14,0.0) [0.0|1.0737418220000016E-5] "m/s^2" ECU
  SG_ sig_12_4 : 12|4@1- (10000.0,-31622.776601683792) [-111622.77660168378|28377.223398316208] "s" ECU
  SG_ sig_45_2 : 45|2@0- (1.0,0.0) [-2.0|1.0] "" ECU
  SG_ sig_50_5 : 50|5@1+ (1.0,0.0) [0.0|30.0] "" ECU
  SG_ sig_55_1 : 55|1@0+ (1.0,0.0) [0.0|1.0] "" ECU
  SG_ sig_49_2 : 49|2@0- (1.0,0.0) [-2.0|1.0] "" ECU

BO_ 1085 frame_1085: 5 Vector__XXX
  SG_ checksum_1_8 : 7|8@0+ (1.0,0.0) [0.0|255.0] "" ECU
  SG_ sig_15_1 : 15|1@0+ (1.0,0.0) [0.0|1.0] "" ECU
  SG_ sig_27_8 : 27|8@0+ (1.0000000000000006E-5,3.1622776601683794E-4) [3.1622776601683794E-4|0.0028562277660168396] "V" ECU
  SG_ sig_11_13 : 11|13@0+ (0.010000000000000002,-31.622776601683793) [-31.622776601683793|50.277223398316224] "A" ECU
  SG_ sig_14_2 : 14|2@0+ (1.0,0.0) [0.0|3.0] "" ECU
  SG_ sig_12_1 : 12|1@0+ (1.0,0.0) [0.0|1.0] "" ECU
  SG_ sig_30_3 : 30|3@0+ (1.0,0.0) [0.0|6.0] "" ECU
  SG_ sig_35_4 : 35|4@0+ (0.1,0.31622776601683794) [0.31622776601683794|1.7162277660168381] "kWh" ECU

BO_ 39 frame_39: 6 Vector__XXX
  SG_ checksum_17_8 : 16|8@1+ (1.0,0.0) [0.0|255.0] "" ECU
  SG_ sig_5_13 : 5|13@0+ (1.0000000000000009E-9,-3.162277660168379E-6) [-3.162277660168379E-6|5.027722339831629E-6] "m/s^2" ECU
  SG_ sig_39_12 : 39|12@0- (1.0000000000000006E-5,0.0) [-0.020480000000000012|0.020460000000000013] "V" ECU
  SG_ sig_31_8 : 31|8@0- (0.1,3.1622776601683795) [-9.63772233983162|15.762277660168381] "s" ECU
  SG_ sig_43_4 : 43|4@0- (1.0000000000000006E-5,-3.1622776601683795E-5) [-1.1162277660168384E-4|2.837722339831624E-5] "W" ECU

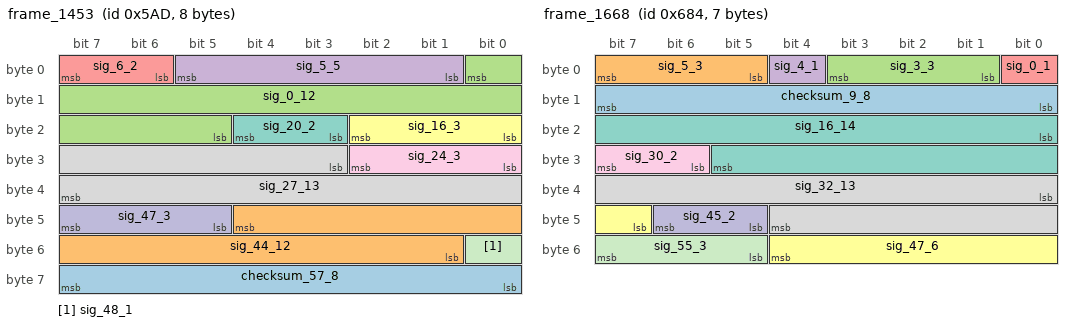
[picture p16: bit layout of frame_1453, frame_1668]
BO_ 1453 frame_1453: 8 Vector__XXX
  SG_ checksum_57_8 : 56|8@1+ (1.0,0.0) [0.0|255.0] "" ECU
  SG_ sig_44_12 : 44|12@0+ (1.0000000000000007E-7,3.1622776601683794E-4) [3.1622776601683794E-4|7.256277660168382E-4] "kWh" ECU
  SG_ sig_0_12 : 0|12@0+ (1.0000000000000005E-4,0.0) [0.0|0.4094000000000002] "kWh" ECU
  SG_ sig_5_5 : 5|5@0- (1000.0,-31622.776601683792) [-47622.77660168379|-17622.776601683792] "A" ECU
  SG_ sig_6_2 : 6|2@1+ (1.0,0.0) [0.0|3.0] "" ECU
  SG_ sig_16_3 : 16|3@1+ (1.0,0.0) [0.0|6.0] "" ECU
  SG_ sig_20_2 : 20|2@0- (1.0,0.0) [-2.0|1.0] "" ECU
  SG_ sig_27_13 : 27|13@1+ (1.0000000000000008E-8,3.1622776601683795E-5) [3.1622776601683795E-5|1.1352277660168385E-4] "m/s^2" ECU
  SG_ sig_24_3 : 24|3@1- (1.0,0.0) [-4.0|2.0] "" ECU
  SG_ sig_47_3 : 47|3@0+ (1.0,0.0) [0.0|6.0] "" ECU
  SG_ sig_48_1 : 48|1@0+ (1.0,0.0) [0.0|1.0] "" ECU

BO_ 1039 frame_1039: 1 Vector__XXX
  SG_ checksum_1_8 : 7|8@0+ (1.0,0.0) [0.0|255.0] "" ECU

BO_ 970 frame_970: 3 ECU
  SG_ checksum_1_8 : 0|8@1+ (1.0,0.0) [0.0|255.0] "" Vector__XXX
  SG_ sig_9_13 : 9|13@1- (1.0000000000000006E-5,0.0) [-0.040960000000000024|0.040940000000000025] "km/h" Vector__XXX
  SG_ sig_8_1 : 8|1@1+ (1.0,0.0) [0.0|1.0] "" Vector__XXX
  SG_ sig_22_2 : 22|2@1- (1.0,0.0) [-2.0|1.0] "" Vector__XXX

BO_ 1668 frame_1668: 7 Vector__XXX
  SG_ checksum_9_8 : 15|8@0+ (1.0,0.0) [0.0|255.0] "" ECU
  SG_ sig_5_3 : 5|3@1+ (1.0,0.0) [0.0|6.0] "" ECU
  SG_ sig_3_3 : 3|3@0+ (1.0,0.0) [0.0|6.0] "" ECU
  SG_ sig_4_1 : 4|1@0+ (1.0,0.0) [0.0|1.0] "" ECU
  SG_ sig_0_1 : 0|1@1+ (1.0,0.0) [0.0|1.0] "" ECU
  SG_ sig_47_6 : 47|6@1- (1.0,0.0) [-32.0|30.0] "" ECU
  SG_ sig_16_14 : 16|14@1+ (10.0,0.0) [0.0|163820.0] "m/s^2" ECU
  SG_ sig_32_13 : 32|13@1+ (1.0000000000000007E-7,0.0) [0.0|8.190000000000006E-4] "m/s^2" ECU
  SG_ sig_30_2 : 30|2@1- (1.0,0.0) [-2.0|1.0] "" ECU
  SG_ sig_45_2 : 45|2@1+ (1.0,0.0) [0.0|3.0] "" ECU
  SG_ sig_55_3 : 55|3@0+ (1.0,0.0) [0.0|6.0] "" ECU

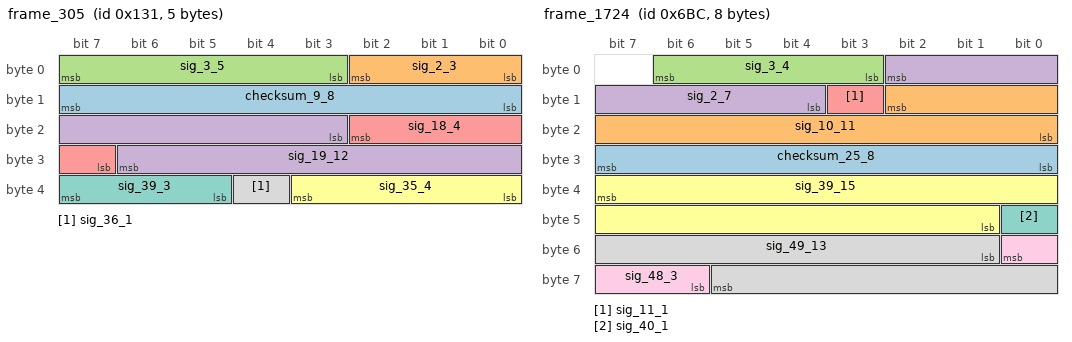
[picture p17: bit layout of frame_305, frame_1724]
BO_ 305 frame_305: 5 ECU
  SG_ checksum_9_8 : 15|8@0+ (1.0,0.0) [0.0|255.0] "" Vector__XXX
  SG_ sig_2_3 : 2|3@0+ (1.0,0.0) [0.0|6.0] "" Vector__XXX
  SG_ sig_3_5 : 3|5@1- (1.0,0.0) [-16.0|14.0] "" Vector__XXX
  SG_ sig_19_12 : 19|12@1+ (1.0,0.0) [0.0|4094.0] "A" Vector__XXX
  SG_ sig_18_4 : 18|4@0- (1.0,0.0) [-8.0|6.0] "" Vector__XXX
  SG_ sig_35_4 : 35|4@0+ (1.0,0.0) [0.0|14.0] "" Vector__XXX
  SG_ sig_39_3 : 39|3@0- (1.0,0.0) [-4.0|2.0] "" Vector__XXX
  SG_ sig_36_1 : 36|1@1+ (1.0,0.0) [0.0|1.0] "" Vector__XXX

BO_ 309 frame_309: 6 ECU
  SG_ checksum_33_8 : 39|8@0+ (1.0,0.0) [0.0|255.0] "" Vector__XXX
  SG_ sig_2_14 : 2|14@0- (0.1,316.22776601683796) [-502.9722339831621|1135.227766016838] "m/s^2" Vector__XXX
  SG_ sig_7_5 : 7|5@0- (1000.0,-31622.776601683792) [-47622.77660168379|-17622.776601683792] "m/s^2" Vector__XXX
  SG_ sig_18_8 : 18|8@0- (1.0,0.0) [-128.0|126.0] "" Vector__XXX
  SG_ sig_20_2 : 20|2@0+ (1.0,0.0) [0.0|3.0] "" Vector__XXX
  SG_ sig_26_2 : 26|2@0- (1.0,0.0) [-2.0|1.0] "" Vector__XXX
  SG_ sig_46_7 : 46|7@0+ (1000.0,31622.776601683792) [31622.776601683792|157622.77660168378] "km/h" Vector__XXX

BO_ 1724 frame_1724: 8 Vector__XXX
  SG_ checksum_25_8 : 24|8@1+ (1.0,0.0) [0.0|255.0] "" ECU
  SG_ sig_10_11 : 10|11@0- (1.0,0.0) [-1024.0|1022.0] "m/s^2" ECU
  SG_ sig_3_4 : 3|4@1- (10.0,0.0) [-80.0|60.0] "A" ECU
  SG_ sig_2_7 : 2|7@0+ (0.1,3.1622776601683795) [3.1622776601683795|15.762277660168381] "A" ECU
  SG_ sig_11_1 : 11|1@1+ (1.0,0.0) [0.0|1.0] "" ECU
  SG_ sig_39_15 : 39|15@0+ (1.0000000000000007E-7,0.0) [0.0|0.0032766000000000023] "W" ECU
  SG_ sig_40_1 : 40|1@1+ (1.0,0.0) [0.0|1.0] "" ECU
  SG_ sig_49_13 : 49|13@1+ (1.0,0.0) [0.0|8190.0] "" ECU
  SG_ sig_48_3 : 48|3@0+ (1.0,0.0) [0.0|6.0] "" ECU

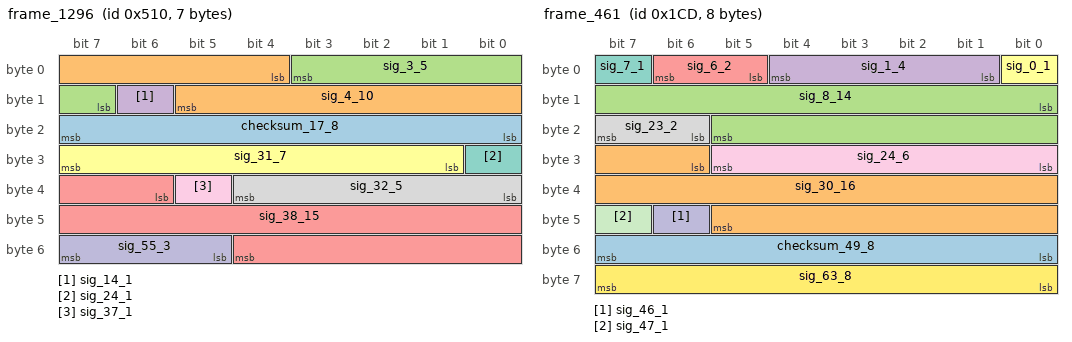
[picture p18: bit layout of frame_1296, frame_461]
BO_ 1296 frame_1296: 7 Vector__XXX
  SG_ checksum_17_8 : 23|8@0+ (1.0,0.0) [0.0|255.0] "" ECU
  SG_ sig_4_10 : 4|10@1+ (0.0010000000000000002,0.31622776601683794) [0.31622776601683794|1.3382277660168382] "W" ECU
  SG_ sig_3_5 : 3|5@0- (1000.0,31622.776601683792) [15622.776601683792|45622.77660168379] "A" ECU
  SG_ sig_14_1 : 14|1@0+ (1.0,0.0) [0.0|1.0] "" ECU
  SG_ sig_38_15 : 38|15@1+ (0.1,-3162.2776601683795) [-3162.2776601683795|114.32233983162087] "A" ECU
  SG_ sig_31_7 : 31|7@0+ (1.0000000000000005E-4,-0.0031622776601683794) [-0.0031622776601683794|0.009437722339831625] "kWh" ECU
  SG_ sig_24_1 : 24|1@0+ (1.0,0.0) [0.0|1.0] "" ECU
  SG_ sig_32_5 : 32|5@1+ (0.010000000000000002,0.31622776601683794) [0.31622776601683794|0.616227766016838] "kWh" ECU
  SG_ sig_37_1 : 37|1@0+ (1.0,0.0) [0.0|1.0] "" ECU
  SG_ sig_55_3 : 55|3@0+ (1.0,0.0) [0.0|6.0] "" ECU

BO_ 461 frame_461: 8 Vector__XXX
  SG_ checksum_49_8 : 55|8@0+ (1.0,0.0) [0.0|255.0] "" ECU
  SG_ sig_30_16 : 30|16@1+ (1.0,0.0) [0.0|65534.0] "" ECU
  SG_ sig_8_14 : 8|14@1+ (1.0,0.0) [0.0|16382.0] "" ECU
  SG_ sig_1_4 : 1|4@1- (1.0000000000000005E-4,3.1622776601683794E-4) [-4.837722339831624E-4|9.162277660168382E-4] "s" ECU
  SG_ sig_6_2 : 6|2@0- (1.0,0.0) [-2.0|1.0] "" ECU
  SG_ sig_0_1 : 0|1@1+ (1.0,0.0) [0.0|1.0] "" ECU
  SG_ sig_7_1 : 7|1@1+ (1.0,0.0) [0.0|1.0] "" ECU
  SG_ sig_23_2 : 23|2@0- (1.0,0.0) [-2.0|1.0] "" ECU
  SG_ sig_24_6 : 24|6@1+ (1.0,0.0) [0.0|62.0] "" ECU
  SG_ sig_46_1 : 46|1@1+ (1.0,0.0) [0.0|1.0] "" ECU
  SG_ sig_47_1 : 47|1@1+ (1.0,0.0) [0.0|1.0] "" ECU
  SG_ sig_63_8 : 63|8@0- (1.0000000000000006E-5,0.0) [-0.0012800000000000008|0.0012600000000000007] "m/s^2" ECU

BO_ 231 frame_231: 1 ECU
  SG_ checksum_1_8 : 0|8@1+ (1.0,0.0) [0.0|255.0] "" Vector__XXX

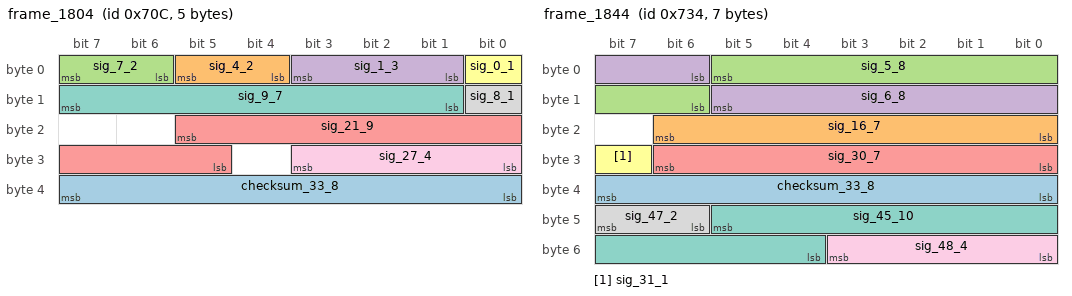
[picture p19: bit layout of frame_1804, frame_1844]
BO_ 1804 frame_1804: 5 Vector__XXX
  SG_ checksum_33_8 : 32|8@1+ (1.0,0.0) [0.0|255.0] "" ECU
  SG_ sig_4_2 : 4|2@1+ (1.0,0.0) [0.0|3.0] "" ECU
  SG_ sig_7_2 : 7|2@0+ (1.0,0.0) [0.0|3.0] "" ECU
  SG_ sig_1_3 : 1|3@1- (1.0,0.0) [-4.0|2.0] "" ECU
  SG_ sig_21_9 : 21|9@0- (1.0,0.0) [-256.0|254.0] "" ECU
  SG_ sig_0_1 : 0|1@1+ (1.0,0.0) [0.0|1.0] "" ECU
  SG_ sig_9_7 : 9|7@1- (0.1,3.1622776601683795) [-3.237722339831621|9.36227766016838] "kWh" ECU
  SG_ sig_8_1 : 8|1@1+ (1.0,0.0) [0.0|1.0] "" ECU
  SG_ sig_27_4 : 27|4@0+ (0.010000000000000002,0.03162277660168379) [0.03162277660168379|0.1716227766016838] "W" ECU

BO_ 1530 frame_1530: 7 ECU
  SG_ checksum_33_8 : 32|8@1+ (1.0,0.0) [0.0|255.0] "" Vector__XXX
  SG_ sig_8_17 : 8|17@0- (0.1,3162.2776601683795) [-3391.322339831621|9715.67766016838] "V" Vector__XXX
  SG_ sig_0_8 : 0|8@1- (1.0000000000000006E-5,-3.1622776601683794E-4) [-0.0015962277660168387|9.437722339831628E-4] "W" Vector__XXX
  SG_ sig_9_6 : 9|6@1+ (1000.0,31622.776601683792) [31622.776601683792|93622.77660168378] "kWh" Vector__XXX
  SG_ sig_15_1 : 15|1@0+ (1.0,0.0) [0.0|1.0] "" Vector__XXX
  SG_ sig_44_13 : 44|13@0- (10.0,-31622.776601683792) [-72582.77660168378|9317.223398316208] "m/s^2" Vector__XXX
  SG_ sig_47_3 : 47|3@0- (1.0,0.0) [-4.0|2.0] "" Vector__XXX

BO_ 496 frame_496: 5 Vector__XXX
  SG_ checksum_25_8 : 31|8@0+ (1.0,0.0) [0.0|255.0] "" ECU
  SG_ sig_12_11 : 12|11@1+ (1.0000000000000007E-7,0.0) [0.0|2.0460000000000015E-4] "kWh" ECU
  SG_ sig_7_7 : 7|7@0- (1.0000000000000006E-5,3.1622776601683794E-4) [-3.2377223398316244E-4|9.362277660168383E-4] "A" ECU
  SG_ sig_8_4 : 8|4@1- (10000.0,31622.776601683792) [-48377.22339831621|91622.77660168378] "kWh" ECU
  SG_ sig_23_1 : 23|1@0+ (1.0,0.0) [0.0|1.0] "" ECU
  SG_ sig_32_8 : 32|8@1- (1.0,0.0) [-128.0|126.0] "W" ECU

BO_ 777 frame_777: 1 Vector__XXX
  SG_ checksum_1_8 : 0|8@1+ (1.0,0.0) [0.0|255.0] "" ECU

BO_ 1844 frame_1844: 7 Vector__XXX
  SG_ checksum_33_8 : 39|8@0+ (1.0,0.0) [0.0|255.0] "" ECU
  SG_ sig_16_7 : 16|7@1- (0.0010000000000000002,-0.03162277660168379) [-0.0956227766016838|0.030377223398316222] "s" ECU
  SG_ sig_5_8 : 5|8@0- (1.0,0.0) [-128.0|126.0] "" ECU
  SG_ sig_6_8 : 6|8@1- (1.0,-31.622776601683793) [-159.6227766016838|94.3772233983162] "W" ECU
  SG_ sig_30_7 : 30|7@0+ (1.0,0.0) [0.0|126.0] "" ECU
  SG_ sig_31_1 : 31|1@1+ (1.0,0.0) [0.0|1.0] "" ECU
  SG_ sig_45_10 : 45|10@0+ (1.0000000000000006E-6,-3.1622776601683794E-4) [-3.1622776601683794E-4|7.057722339831626E-4] "V" ECU
  SG_ sig_47_2 : 47|2@0+ (1.0,0.0) [0.0|3.0] "" ECU
  SG_ sig_48_4 : 48|4@1+ (1.0,0.0) [0.0|14.0] "" ECU

BO_ 511 frame_511: 3 Vector__XXX
  SG_ checksum_9_8 : 15|8@0+ (1.0,0.0) [0.0|255.0] "" ECU
  SG_ sig_0_8 : 0|8@1- (10.0,0.0) [-1280.0|1260.0] "km/h" ECU

BO_ 616 frame_616: 6 Vector__XXX
  SG_ checksum_17_8 : 16|8@1+ (1.0,0.0) [0.0|255.0] "" ECU
  SG_ sig_4_10 : 4|10@1- (1.0000000000000005E-4,0.03162277660168379) [-0.019577223398316232|0.08262277660168382] "km/h" ECU
  SG_ sig_14_2 : 14|2@1+ (1.0,0.0) [0.0|3.0] "" ECU
  SG_ sig_33_8 : 33|8@1- (1.0,0.0) [-128.0|126.0] "" ECU
  SG_ sig_25_8 : 25|8@1- (1.0000000000000006E-6,3.1622776601683795E-5) [-9.637722339831629E-5|1.5762277660168387E-4] "s" ECU
  SG_ sig_46_2 : 46|2@1+ (1.0,0.0) [0.0|3.0] "" ECU

BO_ 934 frame_934: 7 Vector__XXX
  SG_ checksum_17_8 : 16|8@1+ (1.0,0.0) [0.0|255.0] "" ECU
  SG_ sig_2_10 : 2|10@1+ (1.0000000000000006E-6,-3.1622776601683794E-4) [-3.1622776601683794E-4|7.057722339831626E-4] "W" ECU
  SG_ sig_12_4 : 12|4@1+ (0.0010000000000000002,0.0) [0.0|0.014000000000000004] "V" ECU
  SG_ sig_25_18 : 25|18@1- (1.0,0.0) [-131072.0|131070.0] "" ECU
  SG_ sig_24_1 : 24|1@1+ (1.0,0.0) [0.0|1.0] "" ECU
  SG_ sig_43_12 : 43|12@1- (1.0,0.0) [-2048.0|2046.0] "" ECU
  SG_ sig_55_1 : 55|1@1+ (1.0,0.0) [0.0|1.0] "" ECU

CM_ BO_ 1249 "Randomly defined CAN frame";
CM_ SG_ 1249 checksum_17_8 "8 Bit checksum for protection of frame contents";
CM_ BO_ 579 "Randomly defined CAN frame";
CM_ SG_ 579 checksum_25_8 "8 Bit checksum for protection of frame contents";
CM_ BO_ 392 "Randomly defined CAN frame";
CM_ SG_ 392 checksum_57_8 "8 Bit checksum for protection of frame contents";
CM_ BO_ 891 "Randomly defined CAN frame";
CM_ SG_ 891 checksum_9_8 "8 Bit checksum for protection of frame contents";
CM_ BO_ 1082 "Randomly defined CAN frame";
CM_ SG_ 1082 checksum_1_8 "8 Bit checksum for protection of frame contents";
CM_ BO_ 878 "Randomly defined CAN frame";
CM_ SG_ 878 checksum_17_8 "8 Bit checksum for protection of frame contents";
CM_ BO_ 299 "Randomly defined CAN frame";
CM_ SG_ 299 checksum_1_8 "8 Bit checksum for protection of frame contents";
CM_ BO_ 1921 "Randomly defined CAN frame";
CM_ SG_ 1921 checksum_1_8 "8 Bit checksum for protection of frame contents";
CM_ BO_ 754 "Randomly defined CAN frame";
CM_ SG_ 754 checksum_9_8 "8 Bit checksum for protection of frame contents";
CM_ BO_ 838 "Randomly defined CAN frame";
CM_ SG_ 838 checksum_17_8 "8 Bit checksum for protection of frame contents";
CM_ BO_ 33 "Randomly defined CAN frame";
CM_ SG_ 33 checksum_9_8 "8 Bit checksum for protection of frame contents";
CM_ BO_ 1076 "Randomly defined CAN frame";
CM_ SG_ 1076 checksum_9_8 "8 Bit checksum for protection of frame contents";
CM_ BO_ 16 "Randomly defined CAN frame";
CM_ SG_ 16 checksum_17_8 "8 Bit checksum for protection of frame contents";
CM_ BO_ 1578 "Randomly defined CAN frame";
CM_ SG_ 1578 checksum_57_8 "8 Bit checksum for protection of frame contents";
CM_ BO_ 1550 "Randomly defined CAN frame";
CM_ SG_ 1550 checksum_49_8 "8 Bit checksum for protection of frame contents";
CM_ BO_ 1636 "Randomly defined CAN frame";
CM_ SG_ 1636 checksum_17_8 "8 Bit checksum for protection of frame contents";
CM_ BO_ 24 "Randomly defined CAN frame";
CM_ SG_ 24 checksum_33_8 "8 Bit checksum for protection of frame contents";
CM_ BO_ 880 "Randomly defined CAN frame";
CM_ SG_ 880 checksum_9_8 "8 Bit checksum for protection of frame contents";
CM_ BO_ 575 "Randomly defined CAN frame";
CM_ SG_ 575 checksum_1_8 "8 Bit checksum for protection of frame contents";
CM_ BO_ 931 "Randomly defined CAN frame";
CM_ SG_ 931 checksum_33_8 "8 Bit checksum for protection of frame contents";
CM_ BO_ 525 "Randomly defined CAN frame";
CM_ SG_ 525 checksum_9_8 "8 Bit checksum for protection of frame contents";
CM_ BO_ 1645 "Randomly defined CAN frame";
CM_ SG_ 1645 checksum_9_8 "8 Bit checksum for protection of frame contents";
CM_ BO_ 646 "Randomly defined CAN frame";
CM_ SG_ 646 checksum_17_8 "8 Bit checksum for protection of frame contents";
CM_ BO_ 85 "Randomly defined CAN frame";
CM_ SG_ 85 checksum_1_8 "8 Bit checksum for protection of frame contents";
CM_ BO_ 1832 "Randomly defined CAN frame";
CM_ SG_ 1832 checksum_49_8 "8 Bit checksum for protection of frame contents";
CM_ BO_ 1598 "Randomly defined CAN frame";
CM_ SG_ 1598 checksum_1_8 "8 Bit checksum for protection of frame contents";
CM_ BO_ 696 "Randomly defined CAN frame";
CM_ SG_ 696 checksum_1_8 "8 Bit checksum for protection of frame contents";
CM_ BO_ 1933 "Randomly defined CAN frame";
CM_ SG_ 1933 checksum_9_8 "8 Bit checksum for protection of frame contents";
CM_ BO_ 991 "Randomly defined CAN frame";
CM_ SG_ 991 checksum_1_8 "8 Bit checksum for protection of frame contents";
CM_ BO_ 1959 "Randomly defined CAN frame";
CM_ SG_ 1959 checksum_1_8 "8 Bit checksum for protection of frame contents";
CM_ BO_ 748 "Randomly defined CAN frame";
CM_ SG_ 748 checksum_33_8 "8 Bit checksum for protection of frame contents";
CM_ BO_ 1566 "Randomly defined CAN frame";
CM_ SG_ 1566 checksum_17_8 "8 Bit checksum for protection of frame contents";
CM_ BO_ 722 "Randomly defined CAN frame";
CM_ SG_ 722 checksum_9_8 "8 Bit checksum for protection of frame contents";
CM_ BO_ 632 "Randomly defined CAN frame";
CM_ SG_ 632 checksum_17_8 "8 Bit checksum for protection of frame contents";
CM_ BO_ 1388 "Randomly defined CAN frame";
CM_ SG_ 1388 checksum_1_8 "8 Bit checksum for protection of frame contents";
CM_ BO_ 1817 "Randomly defined CAN frame";
CM_ SG_ 1817 checksum_9_8 "8 Bit checksum for protection of frame contents";
CM_ BO_ 755 "Randomly defined CAN frame";
CM_ SG_ 755 checksum_25_8 "8 Bit checksum for protection of frame contents";
CM_ BO_ 1910 "Randomly defined CAN frame";
CM_ SG_ 1910 checksum_25_8 "8 Bit checksum for protection of frame contents";
CM_ BO_ 966 "Randomly defined CAN frame";
CM_ SG_ 966 checksum_17_8 "8 Bit checksum for protection of frame contents";
CM_ BO_ 75 "Randomly defined CAN frame";
CM_ SG_ 75 checksum_49_8 "8 Bit checksum for protection of frame contents";
CM_ BO_ 1961 "Randomly defined CAN frame";
CM_ SG_ 1961 checksum_49_8 "8 Bit checksum for protection of frame contents";
CM_ BO_ 1687 "Randomly defined CAN frame";
CM_ SG_ 1687 checksum_41_8 "8 Bit checksum for protection of frame contents";
CM_ BO_ 1946 "Randomly defined CAN frame";
CM_ SG_ 1946 checksum_9_8 "8 Bit checksum for protection of frame contents";
CM_ BO_ 1663 "Randomly defined CAN frame";
CM_ SG_ 1663 checksum_1_8 "8 Bit checksum for protection of frame contents";
CM_ BO_ 1193 "Randomly defined CAN frame";
CM_ SG_ 1193 checksum_1_8 "8 Bit checksum for protection of frame contents";
CM_ BO_ 95 "Randomly defined CAN frame";
CM_ SG_ 95 checksum_1_8 "8 Bit checksum for protection of frame contents";
CM_ BO_ 1510 "Randomly defined CAN frame";
CM_ SG_ 1510 checksum_1_8 "8 Bit checksum for protection of frame contents";
CM_ BO_ 1678 "Randomly defined CAN frame";
CM_ SG_ 1678 checksum_25_8 "8 Bit checksum for protection of frame contents";
CM_ BO_ 1812 "Randomly defined CAN frame";
CM_ SG_ 1812 checksum_41_8 "8 Bit checksum for protection of frame contents";
CM_ BO_ 1131 "Randomly defined CAN frame";
CM_ SG_ 1131 checksum_1_8 "8 Bit checksum for protection of frame contents";
CM_ BO_ 625 "Randomly defined CAN frame";
CM_ SG_ 625 checksum_1_8 "8 Bit checksum for protection of frame contents";
CM_ BO_ 204 "Randomly defined CAN frame";
CM_ SG_ 204 checksum_25_8 "8 Bit checksum for protection of frame contents";
CM_ BO_ 1700 "Randomly defined CAN frame";
CM_ SG_ 1700 checksum_1_8 "8 Bit checksum for protection of frame contents";
CM_ BO_ 1460 "Randomly defined CAN frame";
CM_ SG_ 1460 checksum_9_8 "8 Bit checksum for protection of frame contents";
CM_ BO_ 1600 "Randomly defined CAN frame";
CM_ SG_ 1600 checksum_33_8 "8 Bit checksum for protection of frame contents";
CM_ BO_ 653 "Randomly defined CAN frame";
CM_ SG_ 653 checksum_17_8 "8 Bit checksum for protection of frame contents";
CM_ BO_ 699 "Randomly defined CAN frame";
CM_ SG_ 699 checksum_9_8 "8 Bit checksum for protection of frame contents";
CM_ BO_ 1307 "Randomly defined CAN frame";
CM_ SG_ 1307 checksum_41_8 "8 Bit checksum for protection of frame contents";
CM_ BO_ 1414 "Randomly defined CAN frame";
CM_ SG_ 1414 checksum_1_8 "8 Bit checksum for protection of frame contents";
CM_ BO_ 1085 "Randomly defined CAN frame";
CM_ SG_ 1085 checksum_1_8 "8 Bit checksum for protection of frame contents";
CM_ BO_ 39 "Randomly defined CAN frame";
CM_ SG_ 39 checksum_17_8 "8 Bit checksum for protection of frame contents";
CM_ BO_ 1453 "Randomly defined CAN frame";
CM_ SG_ 1453 checksum_57_8 "8 Bit checksum for protection of frame contents";
CM_ BO_ 1039 "Randomly defined CAN frame";
CM_ SG_ 1039 checksum_1_8 "8 Bit checksum for protection of frame contents";
CM_ BO_ 970 "Randomly defined CAN frame";
CM_ SG_ 970 checksum_1_8 "8 Bit checksum for protection of frame contents";
CM_ BO_ 1668 "Randomly defined CAN frame";
CM_ SG_ 1668 checksum_9_8 "8 Bit checksum for protection of frame contents";
CM_ BO_ 305 "Randomly defined CAN frame";
CM_ SG_ 305 checksum_9_8 "8 Bit checksum for protection of frame contents";
CM_ BO_ 309 "Randomly defined CAN frame";
CM_ SG_ 309 checksum_33_8 "8 Bit checksum for protection of frame contents";
CM_ BO_ 1724 "Randomly defined CAN frame";
CM_ SG_ 1724 checksum_25_8 "8 Bit checksum for protection of frame contents";
CM_ BO_ 1296 "Randomly defined CAN frame";
CM_ SG_ 1296 checksum_17_8 "8 Bit checksum for protection of frame contents";
CM_ BO_ 461 "Randomly defined CAN frame";
CM_ SG_ 461 checksum_49_8 "8 Bit checksum for protection of frame contents";
CM_ BO_ 231 "Randomly defined CAN frame";
CM_ SG_ 231 checksum_1_8 "8 Bit checksum for protection of frame contents";
CM_ BO_ 1804 "Randomly defined CAN frame";
CM_ SG_ 1804 checksum_33_8 "8 Bit checksum for protection of frame contents";
CM_ BO_ 1530 "Randomly defined CAN frame";
CM_ SG_ 1530 checksum_33_8 "8 Bit checksum for protection of frame contents";
CM_ BO_ 496 "Randomly defined CAN frame";
CM_ SG_ 496 checksum_25_8 "8 Bit checksum for protection of frame contents";
CM_ BO_ 777 "Randomly defined CAN frame";
CM_ SG_ 777 checksum_1_8 "8 Bit checksum for protection of frame contents";
CM_ BO_ 1844 "Randomly defined CAN frame";
CM_ SG_ 1844 checksum_33_8 "8 Bit checksum for protection of frame contents";
CM_ BO_ 511 "Randomly defined CAN frame";
CM_ SG_ 511 checksum_9_8 "8 Bit checksum for protection of frame contents";
CM_ BO_ 616 "Randomly defined CAN frame";
CM_ SG_ 616 checksum_17_8 "8 Bit checksum for protection of frame contents";
CM_ BO_ 934 "Randomly defined CAN frame";
CM_ SG_ 934 checksum_17_8 "8 Bit checksum for protection of frame contents";
BA_DEF_ "Author" STRING;
BA_DEF_ BO_ "frameSendMode" ENUM  "regular","event","mixed";
BA_DEF_ BO_ "sendPeriod" INT 5 10000;
BA_DEF_ BO_ "crcStartValue" INT 1 255;
BA_DEF_ BO_ "eventMinDistance" INT 5 10000;
BA_DEF_ SG_ "initialValue" FLOAT -1e38 1e38;
BA_DEF_DEF_ "Author" "http://sourceforge.net/projects/comframe/";
BA_DEF_DEF_ "frameSendMode" "regular";
BA_DEF_DEF_ "sendPeriod" 10;
BA_DEF_DEF_ "crcStartValue" 1;
BA_DEF_DEF_ "eventMinDistance" 10;
BA_DEF_DEF_ "initialValue" 0.0;
BA_ "frameSendMode" BO_ 1249 1;
BA_ "eventMinDistance" BO_ 1249 500;
BA_ "crcStartValue" BO_ 1249 139;
BA_ "initialValue" SG_ 1249 sig_0_16 0.0011112776601683778;
BA_ "initialValue" SG_ 1249 sig_27_9 -192.0;
BA_ "initialValue" SG_ 1249 sig_28_6 290.0;
BA_ "sendPeriod" BO_ 579 50;
BA_ "crcStartValue" BO_ 579 167;
BA_ "initialValue" SG_ 579 sig_9_4 -1.0;
BA_ "initialValue" SG_ 579 sig_0_9 181.0;
BA_ "initialValue" SG_ 579 sig_13_10 584.0;
BA_ "initialValue" SG_ 579 sig_34_5 -0.03262277660168379;
BA_ "initialValue" SG_ 579 sig_32_2 1.0;
BA_ "initialValue" SG_ 579 sig_39_1 1.0;
BA_ "sendPeriod" BO_ 392 20;
BA_ "crcStartValue" BO_ 392 162;
BA_ "initialValue" SG_ 392 sig_46_7 5.637722339831621;
BA_ "initialValue" SG_ 392 sig_34_2 2.0;
BA_ "initialValue" SG_ 392 sig_0_9 1.8822776601683793;
BA_ "initialValue" SG_ 392 sig_9_4 -0.11622776601683793;
BA_ "initialValue" SG_ 392 sig_22_1 1.0;
BA_ "initialValue" SG_ 392 sig_33_1 1.0;
BA_ "initialValue" SG_ 392 sig_37_5 0.39622776601683796;
BA_ "initialValue" SG_ 392 sig_53_3 1.0;
BA_ "crcStartValue" BO_ 891 48;
BA_ "initialValue" SG_ 891 sig_0_7 1000.0;
BA_ "initialValue" SG_ 891 sig_25_30 3.40149236016838E-5;
BA_ "initialValue" SG_ 891 sig_20_11 -577.0;
BA_ "initialValue" SG_ 891 sig_22_2 1.0;
BA_ "initialValue" SG_ 891 sig_56_3 3.0;
BA_ "frameSendMode" BO_ 1082 2;
BA_ "sendPeriod" BO_ 1082 50;
BA_ "eventMinDistance" BO_ 1082 50;
BA_ "crcStartValue" BO_ 1082 35;
BA_ "initialValue" SG_ 1082 sig_38_12 -44.0;
BA_ "initialValue" SG_ 1082 sig_10_11 -2180.0;
BA_ "initialValue" SG_ 1082 sig_22_8 24.0;
BA_ "initialValue" SG_ 1082 sig_39_4 3.0;
BA_ "sendPeriod" BO_ 878 10000;
BA_ "crcStartValue" BO_ 878 170;
BA_ "initialValue" SG_ 878 sig_7_16 -19.55377660168379;
BA_ "initialValue" SG_ 878 sig_24_13 -2382.0;
BA_ "initialValue" SG_ 878 sig_39_2 2.0;
BA_ "sendPeriod" BO_ 299 1000;
BA_ "crcStartValue" BO_ 299 26;
BA_ "initialValue" SG_ 299 sig_22_27 1.4789523560168396E-4;
BA_ "initialValue" SG_ 299 sig_10_9 -171.0;
BA_ "initialValue" SG_ 299 sig_8_2 1.0;
BA_ "initialValue" SG_ 299 sig_19_3 5.0;
BA_ "initialValue" SG_ 299 sig_52_12 1378.0;
BA_ "initialValue" SG_ 299 sig_49_3 -2.0;
BA_ "sendPeriod" BO_ 1921 5;
BA_ "crcStartValue" BO_ 1921 24;
BA_ "initialValue" SG_ 1921 sig_9_7 95.6227766016838;
BA_ "initialValue" SG_ 1921 sig_8_1 1.0;
BA_ "sendPeriod" BO_ 754 100;
BA_ "crcStartValue" BO_ 754 49;
BA_ "initialValue" SG_ 754 sig_5_6 18.0;
BA_ "initialValue" SG_ 754 sig_7_2 1.0;
BA_ "initialValue" SG_ 754 sig_20_13 -27262.776601683792;
BA_ "frameSendMode" BO_ 838 2;
BA_ "sendPeriod" BO_ 838 50;
BA_ "eventMinDistance" BO_ 838 50;
BA_ "crcStartValue" BO_ 838 120;
BA_ "initialValue" SG_ 838 sig_4_11 1.1772233983162371E-7;
BA_ "initialValue" SG_ 838 sig_6_2 3.0;
BA_ "initialValue" SG_ 838 sig_44_10 -364.0;
BA_ "initialValue" SG_ 838 sig_45_1 1.0;
BA_ "initialValue" SG_ 838 sig_49_2 -1.0;
BA_ "initialValue" SG_ 838 sig_50_1 1.0;
BA_ "sendPeriod" BO_ 33 1000;
BA_ "crcStartValue" BO_ 33 125;
BA_ "initialValue" SG_ 33 sig_7_8 1.600000000000001E-4;
BA_ "initialValue" SG_ 33 sig_21_11 -80.4227766016838;
BA_ "initialValue" SG_ 33 sig_23_2 -1.0;
BA_ "initialValue" SG_ 33 sig_26_3 2.0;
BA_ "sendPeriod" BO_ 1076 500;
BA_ "crcStartValue" BO_ 1076 99;
BA_ "initialValue" SG_ 1076 sig_1_5 15.0;
BA_ "initialValue" SG_ 1076 sig_6_2 1.0;
BA_ "initialValue" SG_ 1076 sig_22_13 3996.0;
BA_ "initialValue" SG_ 1076 sig_24_2 2.0;
BA_ "initialValue" SG_ 1076 sig_23_1 1.0;
BA_ "sendPeriod" BO_ 16 20;
BA_ "crcStartValue" BO_ 16 149;
BA_ "initialValue" SG_ 16 sig_0_13 -24090.0;
BA_ "initialValue" SG_ 16 sig_13_3 -1.0;
BA_ "initialValue" SG_ 16 sig_29_26 18814.060398316222;
BA_ "initialValue" SG_ 16 sig_51_4 151622.77660168378;
BA_ "crcStartValue" BO_ 1578 216;
BA_ "initialValue" SG_ 1578 sig_29_13 -42.300000000000004;
BA_ "initialValue" SG_ 1578 sig_7_10 125.0;
BA_ "initialValue" SG_ 1578 sig_12_14 200.20000000000002;
BA_ "initialValue" SG_ 1578 sig_13_1 1.0;
BA_ "initialValue" SG_ 1578 sig_32_1 1.0;
BA_ "initialValue" SG_ 1578 sig_48_2 2.0;
BA_ "initialValue" SG_ 1578 sig_55_1 1.0;
BA_ "sendPeriod" BO_ 1550 10000;
BA_ "crcStartValue" BO_ 1550 87;
BA_ "initialValue" SG_ 1550 sig_3_1 1.0;
BA_ "initialValue" SG_ 1550 sig_7_4 1216.227766016838;
BA_ "initialValue" SG_ 1550 sig_36_9 0.0514227766016838;
BA_ "initialValue" SG_ 1550 sig_15_14 -3171.0;
BA_ "initialValue" SG_ 1550 sig_2_3 1.0;
BA_ "initialValue" SG_ 1550 sig_31_10 -0.3440000000000001;
BA_ "initialValue" SG_ 1550 sig_16_2 -2.0;
BA_ "initialValue" SG_ 1550 sig_56_8 -91.0;
BA_ "sendPeriod" BO_ 1636 50;
BA_ "crcStartValue" BO_ 1636 133;
BA_ "initialValue" SG_ 1636 sig_1_13 -0.06202776601683785;
BA_ "initialValue" SG_ 1636 sig_0_3 2.0;
BA_ "initialValue" SG_ 1636 sig_38_8 -89000.0;
BA_ "initialValue" SG_ 1636 sig_24_4 -4.8377223398316255E-6;
BA_ "initialValue" SG_ 1636 sig_37_4 1.4000000000000001;
BA_ "initialValue" SG_ 1636 sig_33_4 -8.0;
BA_ "sendPeriod" BO_ 24 25;
BA_ "crcStartValue" BO_ 24 28;
BA_ "initialValue" SG_ 24 sig_8_17 52329.0;
BA_ "initialValue" SG_ 24 sig_0_4 -10.16227766016838;
BA_ "initialValue" SG_ 24 sig_7_3 1.0;
BA_ "initialValue" SG_ 24 sig_25_7 -0.32622776601683795;
BA_ "initialValue" SG_ 24 sig_40_7 109.0;
BA_ "initialValue" SG_ 880 sig_0_7 3.0;
BA_ "initialValue" SG_ 880 sig_29_7 -13.0;
BA_ "initialValue" SG_ 880 sig_21_8 -12600.0;
BA_ "initialValue" SG_ 880 sig_32_7 0.010000000000000002;
BA_ "initialValue" SG_ 880 sig_44_3 -2.0;
BA_ "initialValue" SG_ 880 sig_40_2 -1.0;
BA_ "initialValue" SG_ 880 sig_47_3 5.0;
BA_ "initialValue" SG_ 880 sig_55_15 -341.0;
BA_ "frameSendMode" BO_ 575 2;
BA_ "sendPeriod" BO_ 575 100;
BA_ "eventMinDistance" BO_ 575 100;
BA_ "crcStartValue" BO_ 575 249;
BA_ "initialValue" SG_ 575 sig_8_8 1.4962277660168388E-5;
BA_ "initialValue" SG_ 575 sig_14_6 1.662277660168378E-6;
BA_ "initialValue" SG_ 575 sig_16_6 0.05000000000000001;
BA_ "initialValue" SG_ 575 sig_26_3 -2.0;
BA_ "sendPeriod" BO_ 931 10000;
BA_ "crcStartValue" BO_ 931 99;
BA_ "initialValue" SG_ 931 sig_20_7 776.2277660168379;
BA_ "initialValue" SG_ 931 sig_4_9 125.0;
BA_ "initialValue" SG_ 931 sig_7_3 5.0;
BA_ "initialValue" SG_ 931 sig_24_1 1.0;
BA_ "initialValue" SG_ 931 sig_50_14 9.724277660168385E-6;
BA_ "initialValue" SG_ 931 sig_49_2 -2.0;
BA_ "crcStartValue" BO_ 525 205;
BA_ "initialValue" SG_ 525 sig_0_8 2.7377223398316243E-5;
BA_ "initialValue" SG_ 525 sig_42_1 1.0;
BA_ "initialValue" SG_ 525 sig_20_11 -685.0;
BA_ "initialValue" SG_ 525 sig_17_3 6.0;
BA_ "initialValue" SG_ 525 sig_31_9 3.0500000000000026E-6;
BA_ "initialValue" SG_ 525 sig_47_9 -230.0;
BA_ "sendPeriod" BO_ 1645 5;
BA_ "crcStartValue" BO_ 1645 232;
BA_ "initialValue" SG_ 1645 sig_5_6 2200.0;
BA_ "initialValue" SG_ 1645 sig_7_2 2.0;
BA_ "initialValue" SG_ 1645 sig_23_8 28562.27766016838;
BA_ "sendPeriod" BO_ 646 100;
BA_ "crcStartValue" BO_ 646 255;
BA_ "initialValue" SG_ 646 sig_6_5 12.0;
BA_ "initialValue" SG_ 646 sig_0_2 1.0;
BA_ "initialValue" SG_ 646 sig_7_8 -128.0;
BA_ "initialValue" SG_ 646 sig_15_1 1.0;
BA_ "initialValue" SG_ 646 sig_29_14 0.03135000000000002;
BA_ "initialValue" SG_ 646 sig_30_2 3.0;
BA_ "frameSendMode" BO_ 85 1;
BA_ "eventMinDistance" BO_ 85 50;
BA_ "crcStartValue" BO_ 85 99;
BA_ "initialValue" SG_ 85 sig_8_11 6.507722339831626E-4;
BA_ "initialValue" SG_ 85 sig_10_2 2.0;
BA_ "initialValue" SG_ 85 sig_24_6 93.6227766016838;
BA_ "initialValue" SG_ 85 sig_47_13 1403.0;
BA_ "initialValue" SG_ 85 sig_39_8 -0.9237722339831622;
BA_ "initialValue" SG_ 85 sig_45_4 -71622.77660168378;
BA_ "initialValue" SG_ 85 sig_40_2 1.0;
BA_ "initialValue" SG_ 85 sig_46_1 1.0;
BA_ "initialValue" SG_ 85 sig_61_3 1.0;
BA_ "frameSendMode" BO_ 1832 2;
BA_ "sendPeriod" BO_ 1832 10000;
BA_ "eventMinDistance" BO_ 1832 500;
BA_ "crcStartValue" BO_ 1832 45;
BA_ "initialValue" SG_ 1832 sig_7_17 -55323.0;
BA_ "initialValue" SG_ 1832 sig_33_5 4000.0;
BA_ "initialValue" SG_ 1832 sig_18_14 8.73277660168377E-7;
BA_ "initialValue" SG_ 1832 sig_36_3 3.0;
BA_ "initialValue" SG_ 1832 sig_44_5 3.4622776601683794E-5;
BA_ "initialValue" SG_ 1832 sig_62_7 0.56;
BA_ "initialValue" SG_ 1832 sig_63_1 1.0;
BA_ "frameSendMode" BO_ 1598 2;
BA_ "sendPeriod" BO_ 1598 10000;
BA_ "eventMinDistance" BO_ 1598 1000;
BA_ "crcStartValue" BO_ 1598 27;
BA_ "initialValue" SG_ 1598 sig_10_19 10229.800000000001;
BA_ "initialValue" SG_ 1598 sig_15_5 -416.22776601683796;
BA_ "initialValue" SG_ 1598 sig_35_16 -0.002690700000000002;
BA_ "initialValue" SG_ 1598 sig_39_4 -7162.27766016838;
BA_ "initialValue" SG_ 1598 sig_50_3 5.0;
BA_ "initialValue" SG_ 1598 sig_51_1 1.0;
BA_ "frameSendMode" BO_ 696 2;
BA_ "sendPeriod" BO_ 696 10000;
BA_ "eventMinDistance" BO_ 696 500;
BA_ "crcStartValue" BO_ 696 12;
BA_ "initialValue" SG_ 696 sig_11_13 2.3967223398316255E-6;
BA_ "initialValue" SG_ 696 sig_8_2 -1.0;
BA_ "initialValue" SG_ 696 sig_10_1 1.0;
BA_ "sendPeriod" BO_ 1933 50;
BA_ "crcStartValue" BO_ 1933 33;
BA_ "initialValue" SG_ 1933 sig_1_6 4.56227766016838E-6;
BA_ "initialValue" SG_ 1933 sig_7_1 1.0;
BA_ "initialValue" SG_ 1933 sig_18_15 0.038720000000000025;
BA_ "initialValue" SG_ 1933 sig_39_7 101.0;
BA_ "sendPeriod" BO_ 991 25;
BA_ "crcStartValue" BO_ 991 68;
BA_ "initialValue" SG_ 991 sig_23_23 799.4041000000003;
BA_ "initialValue" SG_ 991 sig_15_8 -9.13772233983163E-6;
BA_ "frameSendMode" BO_ 1959 2;
BA_ "sendPeriod" BO_ 1959 10000;
BA_ "eventMinDistance" BO_ 1959 1000;
BA_ "crcStartValue" BO_ 1959 157;
BA_ "initialValue" SG_ 1959 sig_8_16 -2953.0;
BA_ "crcStartValue" BO_ 748 250;
BA_ "initialValue" SG_ 748 sig_5_6 5.862277660168379;
BA_ "initialValue" SG_ 748 sig_23_7 69.0;
BA_ "initialValue" SG_ 748 sig_13_5 28.0;
BA_ "initialValue" SG_ 748 sig_15_2 1.0;
BA_ "initialValue" SG_ 748 sig_8_1 1.0;
BA_ "initialValue" SG_ 748 sig_29_5 16.622776601683793;
BA_ "initialValue" SG_ 748 sig_16_3 4.0;
BA_ "initialValue" SG_ 748 sig_24_1 1.0;
BA_ "initialValue" SG_ 748 sig_44_11 206.22277660168382;
BA_ "initialValue" SG_ 748 sig_47_3 1.0;
BA_ "initialValue" SG_ 748 sig_49_2 1.0;
BA_ "frameSendMode" BO_ 1566 2;
BA_ "sendPeriod" BO_ 1566 10000;
BA_ "eventMinDistance" BO_ 1566 500;
BA_ "crcStartValue" BO_ 1566 142;
BA_ "initialValue" SG_ 1566 sig_2_12 0.00371427766016838;
BA_ "initialValue" SG_ 1566 sig_1_1 1.0;
BA_ "initialValue" SG_ 1566 sig_0_3 3.0;
BA_ "initialValue" SG_ 1566 sig_29_9 -0.22400000000000006;
BA_ "initialValue" SG_ 1566 sig_28_7 1.622776601683775E-5;
BA_ "sendPeriod" BO_ 722 5;
BA_ "crcStartValue" BO_ 722 165;
BA_ "initialValue" SG_ 722 sig_7_1 1.0;
BA_ "initialValue" SG_ 722 sig_1_2 -2.0;
BA_ "initialValue" SG_ 722 sig_21_24 8.08555339831625E-5;
BA_ "initialValue" SG_ 722 sig_22_2 -2.0;
BA_ "initialValue" SG_ 722 sig_45_11 114.0;
BA_ "initialValue" SG_ 722 sig_49_2 3.0;
BA_ "sendPeriod" BO_ 632 1000;
BA_ "crcStartValue" BO_ 632 80;
BA_ "initialValue" SG_ 632 sig_6_7 10377.223398316208;
BA_ "initialValue" SG_ 632 sig_7_1 1.0;
BA_ "initialValue" SG_ 632 sig_15_6 -4.0;
BA_ "initialValue" SG_ 632 sig_9_2 1.0;
BA_ "initialValue" SG_ 632 sig_46_14 1.0008722339831626;
BA_ "initialValue" SG_ 632 sig_24_9 -88.0;
BA_ "initialValue" SG_ 632 sig_29_5 2.662277660168379E-6;
BA_ "initialValue" SG_ 632 sig_31_2 2.0;
BA_ "initialValue" SG_ 632 sig_62_7 7162.27766016838;
BA_ "sendPeriod" BO_ 1388 500;
BA_ "crcStartValue" BO_ 1388 228;
BA_ "initialValue" SG_ 1388 sig_40_6 -0.2700000000000001;
BA_ "initialValue" SG_ 1388 sig_14_15 -0.0017531776601683784;
BA_ "initialValue" SG_ 1388 sig_24_16 31299.0;
BA_ "initialValue" SG_ 1388 sig_31_7 1.4662277660168381;
BA_ "initialValue" SG_ 1388 sig_50_3 2.0;
BA_ "sendPeriod" BO_ 1817 20;
BA_ "crcStartValue" BO_ 1817 35;
BA_ "initialValue" SG_ 1817 sig_0_8 62622.77660168379;
BA_ "initialValue" SG_ 1817 sig_22_21 -2.726247660168379E-4;
BA_ "initialValue" SG_ 1817 sig_23_1 1.0;
BA_ "initialValue" SG_ 1817 sig_32_2 2.0;
BA_ "sendPeriod" BO_ 755 25;
BA_ "crcStartValue" BO_ 755 40;
BA_ "initialValue" SG_ 755 sig_15_14 3877.0;
BA_ "initialValue" SG_ 755 sig_0_8 198.3772233983162;
BA_ "initialValue" SG_ 755 sig_16_1 1.0;
BA_ "initialValue" SG_ 755 sig_36_4 2.1622776601683795;
BA_ "initialValue" SG_ 755 sig_35_4 8.837722339831628E-6;
BA_ "frameSendMode" BO_ 1910 2;
BA_ "sendPeriod" BO_ 1910 10000;
BA_ "eventMinDistance" BO_ 1910 100;
BA_ "crcStartValue" BO_ 1910 59;
BA_ "initialValue" SG_ 1910 sig_15_6 11.0;
BA_ "initialValue" SG_ 1910 sig_7_8 -87.0;
BA_ "initialValue" SG_ 1910 sig_9_9 3.76227766016838E-4;
BA_ "initialValue" SG_ 1910 sig_39_12 -2.893277660168379E-6;
BA_ "initialValue" SG_ 1910 sig_43_3 -2.0;
BA_ "frameSendMode" BO_ 966 2;
BA_ "sendPeriod" BO_ 966 500;
BA_ "eventMinDistance" BO_ 966 500;
BA_ "crcStartValue" BO_ 966 44;
BA_ "initialValue" SG_ 966 sig_7_15 -33.970000000000006;
BA_ "initialValue" SG_ 966 sig_50_9 101.0;
BA_ "initialValue" SG_ 966 sig_31_8 -94.0;
BA_ "initialValue" SG_ 966 sig_46_10 3.0322776601683795E-4;
BA_ "initialValue" SG_ 966 sig_35_3 4.0;
BA_ "initialValue" SG_ 966 sig_32_2 -1.0;
BA_ "initialValue" SG_ 966 sig_52_2 1.0;
BA_ "initialValue" SG_ 966 sig_56_1 1.0;
BA_ "initialValue" SG_ 966 sig_57_1 1.0;
BA_ "frameSendMode" BO_ 75 1;
BA_ "eventMinDistance" BO_ 75 100;
BA_ "crcStartValue" BO_ 75 93;
BA_ "initialValue" SG_ 75 sig_21_19 474404.0;
BA_ "initialValue" SG_ 75 sig_0_18 -83037.0;
BA_ "initialValue" SG_ 75 sig_42_6 1.0;
BA_ "initialValue" SG_ 75 sig_40_2 3.0;
BA_ "sendPeriod" BO_ 1961 100;
BA_ "crcStartValue" BO_ 1961 213;
BA_ "initialValue" SG_ 1961 sig_30_17 6.853177660168382E-5;
BA_ "initialValue" SG_ 1961 sig_0_10 95.7227766016838;
BA_ "initialValue" SG_ 1961 sig_1_5 -14.0;
BA_ "initialValue" SG_ 1961 sig_6_2 1.0;
BA_ "initialValue" SG_ 1961 sig_22_7 13.772233983162039;
BA_ "initialValue" SG_ 1961 sig_25_5 2.7622776601683788E-6;
BA_ "initialValue" SG_ 1961 sig_57_6 0.05622776601683788;
BA_ "initialValue" SG_ 1961 sig_56_1 1.0;
BA_ "sendPeriod" BO_ 1687 500;
BA_ "crcStartValue" BO_ 1687 247;
BA_ "initialValue" SG_ 1687 sig_7_9 602.2277660168379;
BA_ "initialValue" SG_ 1687 sig_11_14 896.0;
BA_ "initialValue" SG_ 1687 sig_12_2 -2.0;
BA_ "initialValue" SG_ 1687 sig_28_2 -1.0;
BA_ "initialValue" SG_ 1687 sig_52_13 6.164277660168382E-5;
BA_ "initialValue" SG_ 1687 sig_55_2 2.0;
BA_ "frameSendMode" BO_ 1946 2;
BA_ "sendPeriod" BO_ 1946 10000;
BA_ "eventMinDistance" BO_ 1946 1000;
BA_ "crcStartValue" BO_ 1946 222;
BA_ "initialValue" SG_ 1946 sig_7_4 0.0018377223398316216;
BA_ "initialValue" SG_ 1946 sig_3_4 5.0;
BA_ "initialValue" SG_ 1946 sig_48_7 1.600000000000001E-5;
BA_ "initialValue" SG_ 1946 sig_27_17 0.0057469000000000044;
BA_ "initialValue" SG_ 1946 sig_21_10 305.77223398316204;
BA_ "initialValue" SG_ 1946 sig_23_2 -1.0;
BA_ "initialValue" SG_ 1946 sig_42_7 -28.0;
BA_ "initialValue" SG_ 1946 sig_51_3 4.0;
BA_ "initialValue" SG_ 1946 sig_57_1 1.0;
BA_ "initialValue" SG_ 1946 sig_56_1 1.0;
BA_ "sendPeriod" BO_ 1663 25;
BA_ "crcStartValue" BO_ 1663 37;
BA_ "initialValue" SG_ 1663 sig_12_16 31250.0;
BA_ "initialValue" SG_ 1663 sig_8_4 -2.162277660168379E-4;
BA_ "initialValue" SG_ 1663 sig_31_4 -6.000000000000003E-4;
BA_ "sendPeriod" BO_ 1193 100;
BA_ "crcStartValue" BO_ 1193 31;
BA_ "initialValue" SG_ 1193 sig_19_15 -3.113177660168379E-6;
BA_ "initialValue" SG_ 1193 sig_15_5 3662.2776601683795;
BA_ "initialValue" SG_ 1193 sig_10_3 2.0;
BA_ "initialValue" SG_ 1193 sig_16_3 -3.0;
BA_ "initialValue" SG_ 1193 sig_39_6 37.0;
BA_ "initialValue" SG_ 1193 sig_40_10 924.2277660168379;
BA_ "initialValue" SG_ 1193 sig_46_6 46.0;
BA_ "initialValue" SG_ 1193 sig_56_3 6.0;
BA_ "frameSendMode" BO_ 95 2;
BA_ "sendPeriod" BO_ 95 1000;
BA_ "eventMinDistance" BO_ 95 1000;
BA_ "crcStartValue" BO_ 95 213;
BA_ "initialValue" SG_ 95 sig_21_19 6699.91766016838;
BA_ "initialValue" SG_ 95 sig_11_9 2.702277660168379E-6;
BA_ "initialValue" SG_ 95 sig_47_5 11000.0;
BA_ "initialValue" SG_ 95 sig_40_3 1.0;
BA_ "frameSendMode" BO_ 1510 1;
BA_ "eventMinDistance" BO_ 1510 1000;
BA_ "crcStartValue" BO_ 1510 119;
BA_ "initialValue" SG_ 1510 sig_16_6 -0.0013622776601683786;
BA_ "initialValue" SG_ 1510 sig_9_6 -1.0;
BA_ "initialValue" SG_ 1510 sig_8_1 1.0;
BA_ "initialValue" SG_ 1510 sig_19_8 -0.005400000000000002;
BA_ "initialValue" SG_ 1510 sig_17_2 3.0;
BA_ "initialValue" SG_ 1510 sig_62_3 1.0;
BA_ "initialValue" SG_ 1510 sig_38_10 261.0;
BA_ "initialValue" SG_ 1510 sig_32_6 -1562.2776601683795;
BA_ "initialValue" SG_ 1510 sig_55_8 207.0;
BA_ "initialValue" SG_ 1510 sig_56_4 48.377223398316204;
BA_ "initialValue" SG_ 1510 sig_63_1 1.0;
BA_ "sendPeriod" BO_ 1678 500;
BA_ "crcStartValue" BO_ 1678 132;
BA_ "initialValue" SG_ 1678 sig_0_15 -1138.0;
BA_ "initialValue" SG_ 1678 sig_15_8 -48.0;
BA_ "initialValue" SG_ 1678 sig_34_13 3856.2776601683795;
BA_ "initialValue" SG_ 1678 sig_32_2 1.0;
BA_ "initialValue" SG_ 1678 sig_47_1 1.0;
BA_ "frameSendMode" BO_ 1812 2;
BA_ "sendPeriod" BO_ 1812 10000;
BA_ "eventMinDistance" BO_ 1812 500;
BA_ "crcStartValue" BO_ 1812 37;
BA_ "initialValue" SG_ 1812 sig_1_9 -12.3;
BA_ "initialValue" SG_ 1812 sig_0_1 1.0;
BA_ "initialValue" SG_ 1812 sig_10_5 -3.0;
BA_ "initialValue" SG_ 1812 sig_29_7 -18.0;
BA_ "initialValue" SG_ 1812 sig_25_3 -2.0;
BA_ "initialValue" SG_ 1812 sig_36_4 0.017162277660168382;
BA_ "initialValue" SG_ 1812 sig_57_7 123.0;
BA_ "initialValue" SG_ 1812 sig_51_5 -2.6227766016837926;
BA_ "initialValue" SG_ 1812 sig_48_3 -2.0;
BA_ "crcStartValue" BO_ 1131 184;
BA_ "initialValue" SG_ 1131 sig_9_7 1.2000000000000002;
BA_ "initialValue" SG_ 1131 sig_13_3 6.0;
BA_ "initialValue" SG_ 1131 sig_15_2 3.0;
BA_ "initialValue" SG_ 1131 sig_17_18 -4317.422339831621;
BA_ "initialValue" SG_ 1131 sig_42_11 1376.0;
BA_ "initialValue" SG_ 1131 sig_54_2 2.0;
BA_ "initialValue" SG_ 1131 sig_56_5 -5.000000000000004E-7;
BA_ "initialValue" SG_ 1131 sig_61_3 3.0;
BA_ "frameSendMode" BO_ 625 2;
BA_ "sendPeriod" BO_ 625 1000;
BA_ "eventMinDistance" BO_ 625 500;
BA_ "crcStartValue" BO_ 625 121;
BA_ "initialValue" SG_ 625 sig_8_13 744.3000000000001;
BA_ "initialValue" SG_ 625 sig_25_7 76.0;
BA_ "initialValue" SG_ 625 sig_21_4 1.6227766016837846E-4;
BA_ "initialValue" SG_ 625 sig_38_2 3.0;
BA_ "initialValue" SG_ 625 sig_32_5 3.7622776601683796;
BA_ "sendPeriod" BO_ 204 1000;
BA_ "crcStartValue" BO_ 204 173;
BA_ "initialValue" SG_ 204 sig_7_17 13378.0;
BA_ "initialValue" SG_ 204 sig_16_6 -0.02962277660168379;
BA_ "initialValue" SG_ 204 sig_46_2 3.0;
BA_ "initialValue" SG_ 204 sig_35_3 3.0;
BA_ "initialValue" SG_ 204 sig_32_3 1.0;
BA_ "initialValue" SG_ 204 sig_39_6 91.6227766016838;
BA_ "initialValue" SG_ 204 sig_49_7 -62.0;
BA_ "initialValue" SG_ 204 sig_48_1 1.0;
BA_ "frameSendMode" BO_ 1700 2;
BA_ "sendPeriod" BO_ 1700 500;
BA_ "eventMinDistance" BO_ 1700 500;
BA_ "crcStartValue" BO_ 1700 133;
BA_ "initialValue" SG_ 1700 sig_28_28 1.5559247439831647E-4;
BA_ "initialValue" SG_ 1700 sig_14_12 -251.82776601683796;
BA_ "initialValue" SG_ 1700 sig_11_3 3.0;
BA_ "initialValue" SG_ 1700 sig_8_3 -2.0;
BA_ "initialValue" SG_ 1700 sig_56_4 -21.622776601683793;
BA_ "initialValue" SG_ 1700 sig_60_4 -3.162277660168379E-6;
BA_ "sendPeriod" BO_ 1460 50;
BA_ "crcStartValue" BO_ 1460 36;
BA_ "initialValue" SG_ 1460 sig_3_5 -300.0;
BA_ "initialValue" SG_ 1460 sig_0_3 2.0;
BA_ "initialValue" SG_ 1460 sig_16_15 14413.0;
BA_ "frameSendMode" BO_ 1600 2;
BA_ "sendPeriod" BO_ 1600 500;
BA_ "eventMinDistance" BO_ 1600 50;
BA_ "crcStartValue" BO_ 1600 98;
BA_ "initialValue" SG_ 1600 sig_19_9 6.777223398316213;
BA_ "initialValue" SG_ 1600 sig_2_3 -4.0;
BA_ "initialValue" SG_ 1600 sig_29_3 2.0;
BA_ "initialValue" SG_ 1600 sig_46_6 -5.622776601683782E-4;
BA_ "sendPeriod" BO_ 653 500;
BA_ "crcStartValue" BO_ 653 107;
BA_ "initialValue" SG_ 653 sig_3_11 439.22776601683796;
BA_ "initialValue" SG_ 653 sig_4_2 2.0;
BA_ "initialValue" SG_ 653 sig_41_8 86000.0;
BA_ "initialValue" SG_ 653 sig_31_7 55.377223398316204;
BA_ "initialValue" SG_ 653 sig_24_7 2.7000000000000017E-4;
BA_ "initialValue" SG_ 653 sig_42_8 5.0;
BA_ "sendPeriod" BO_ 699 500;
BA_ "crcStartValue" BO_ 699 82;
BA_ "initialValue" SG_ 699 sig_0_8 -1.800000000000001E-5;
BA_ "initialValue" SG_ 699 sig_16_16 0.0050768776601683805;
BA_ "sendPeriod" BO_ 1307 20;
BA_ "crcStartValue" BO_ 1307 59;
BA_ "initialValue" SG_ 1307 sig_9_10 374.0;
BA_ "initialValue" SG_ 1307 sig_2_6 0.005262277660168381;
BA_ "initialValue" SG_ 1307 sig_0_2 -1.0;
BA_ "initialValue" SG_ 1307 sig_8_1 1.0;
BA_ "initialValue" SG_ 1307 sig_20_2 3.0;
BA_ "initialValue" SG_ 1307 sig_31_15 -4.08997766016838;
BA_ "initialValue" SG_ 1307 sig_32_1 1.0;
BA_ "initialValue" SG_ 1307 sig_50_14 11010.0;
BA_ "sendPeriod" BO_ 1414 20;
BA_ "crcStartValue" BO_ 1414 197;
BA_ "initialValue" SG_ 1414 sig_11_30 7.577460410000011E-6;
BA_ "initialValue" SG_ 1414 sig_12_4 -21622.776601683792;
BA_ "initialValue" SG_ 1414 sig_45_2 1.0;
BA_ "initialValue" SG_ 1414 sig_50_5 29.0;
BA_ "initialValue" SG_ 1414 sig_55_1 1.0;
BA_ "initialValue" SG_ 1414 sig_49_2 -1.0;
BA_ "sendPeriod" BO_ 1085 500;
BA_ "crcStartValue" BO_ 1085 109;
BA_ "initialValue" SG_ 1085 sig_15_1 1.0;
BA_ "initialValue" SG_ 1085 sig_27_8 0.0015462277660168386;
BA_ "initialValue" SG_ 1085 sig_11_13 -18.69277660168379;
BA_ "initialValue" SG_ 1085 sig_14_2 2.0;
BA_ "initialValue" SG_ 1085 sig_12_1 1.0;
BA_ "initialValue" SG_ 1085 sig_30_3 3.0;
BA_ "initialValue" SG_ 1085 sig_35_4 0.816227766016838;
BA_ "sendPeriod" BO_ 39 1000;
BA_ "crcStartValue" BO_ 39 11;
BA_ "initialValue" SG_ 39 sig_5_13 -2.972277660168379E-6;
BA_ "initialValue" SG_ 39 sig_39_12 0.008910000000000005;
BA_ "initialValue" SG_ 39 sig_31_8 -3.437722339831621;
BA_ "initialValue" SG_ 39 sig_43_4 -2.162277660168379E-5;
BA_ "sendPeriod" BO_ 1453 100;
BA_ "crcStartValue" BO_ 1453 207;
BA_ "initialValue" SG_ 1453 sig_44_12 4.888277660168381E-4;
BA_ "initialValue" SG_ 1453 sig_0_12 0.39980000000000016;
BA_ "initialValue" SG_ 1453 sig_5_5 -34622.77660168379;
BA_ "initialValue" SG_ 1453 sig_16_3 3.0;
BA_ "initialValue" SG_ 1453 sig_20_2 1.0;
BA_ "initialValue" SG_ 1453 sig_27_13 6.876277660168383E-5;
BA_ "initialValue" SG_ 1453 sig_24_3 1.0;
BA_ "initialValue" SG_ 1453 sig_48_1 1.0;
BA_ "crcStartValue" BO_ 1039 147;
BA_ "frameSendMode" BO_ 970 2;
BA_ "sendPeriod" BO_ 970 10000;
BA_ "eventMinDistance" BO_ 970 500;
BA_ "crcStartValue" BO_ 970 4;
BA_ "initialValue" SG_ 970 sig_9_13 0.010270000000000007;
BA_ "sendPeriod" BO_ 1668 100;
BA_ "crcStartValue" BO_ 1668 130;
BA_ "initialValue" SG_ 1668 sig_5_3 4.0;
BA_ "initialValue" SG_ 1668 sig_3_3 1.0;
BA_ "initialValue" SG_ 1668 sig_0_1 1.0;
BA_ "initialValue" SG_ 1668 sig_47_6 -8.0;
BA_ "initialValue" SG_ 1668 sig_16_14 121520.0;
BA_ "initialValue" SG_ 1668 sig_32_13 2.0860000000000016E-4;
BA_ "initialValue" SG_ 1668 sig_55_3 5.0;
BA_ "crcStartValue" BO_ 305 49;
BA_ "initialValue" SG_ 305 sig_2_3 1.0;
BA_ "initialValue" SG_ 305 sig_3_5 5.0;
BA_ "initialValue" SG_ 305 sig_19_12 1718.0;
BA_ "initialValue" SG_ 305 sig_35_4 7.0;
BA_ "initialValue" SG_ 305 sig_39_3 -1.0;
BA_ "sendPeriod" BO_ 309 100;
BA_ "crcStartValue" BO_ 309 6;
BA_ "initialValue" SG_ 309 sig_2_14 -304.67223398316213;
BA_ "initialValue" SG_ 309 sig_7_5 -44622.77660168379;
BA_ "initialValue" SG_ 309 sig_18_8 -76.0;
BA_ "initialValue" SG_ 309 sig_20_2 3.0;
BA_ "initialValue" SG_ 309 sig_26_2 1.0;
BA_ "initialValue" SG_ 309 sig_46_7 75622.77660168378;
BA_ "frameSendMode" BO_ 1724 2;
BA_ "sendPeriod" BO_ 1724 10000;
BA_ "eventMinDistance" BO_ 1724 1000;
BA_ "crcStartValue" BO_ 1724 2;
BA_ "initialValue" SG_ 1724 sig_10_11 488.0;
BA_ "initialValue" SG_ 1724 sig_3_4 30.0;
BA_ "initialValue" SG_ 1724 sig_2_7 5.66227766016838;
BA_ "initialValue" SG_ 1724 sig_11_1 1.0;
BA_ "initialValue" SG_ 1724 sig_39_15 0.0018952000000000014;
BA_ "initialValue" SG_ 1724 sig_40_1 1.0;
BA_ "initialValue" SG_ 1724 sig_49_13 7864.0;
BA_ "initialValue" SG_ 1724 sig_48_3 5.0;
BA_ "crcStartValue" BO_ 1296 43;
BA_ "initialValue" SG_ 1296 sig_4_10 0.9282277660168381;
BA_ "initialValue" SG_ 1296 sig_3_5 24622.776601683792;
BA_ "initialValue" SG_ 1296 sig_14_1 1.0;
BA_ "initialValue" SG_ 1296 sig_38_15 -1334.8776601683794;
BA_ "initialValue" SG_ 1296 sig_31_7 0.005037722339831624;
BA_ "initialValue" SG_ 1296 sig_24_1 1.0;
BA_ "initialValue" SG_ 1296 sig_32_5 0.476227766016838;
BA_ "initialValue" SG_ 1296 sig_37_1 1.0;
BA_ "initialValue" SG_ 1296 sig_55_3 1.0;
BA_ "crcStartValue" BO_ 461 35;
BA_ "initialValue" SG_ 461 sig_30_16 17951.0;
BA_ "initialValue" SG_ 461 sig_8_14 6752.0;
BA_ "initialValue" SG_ 461 sig_1_4 6.162277660168381E-4;
BA_ "initialValue" SG_ 461 sig_6_2 -1.0;
BA_ "initialValue" SG_ 461 sig_0_1 1.0;
BA_ "initialValue" SG_ 461 sig_23_2 -1.0;
BA_ "initialValue" SG_ 461 sig_24_6 19.0;
BA_ "initialValue" SG_ 461 sig_46_1 1.0;
BA_ "initialValue" SG_ 461 sig_63_8 -6.300000000000004E-4;
BA_ "sendPeriod" BO_ 231 100;
BA_ "crcStartValue" BO_ 231 253;
BA_ "frameSendMode" BO_ 1804 2;
BA_ "sendPeriod" BO_ 1804 1000;
BA_ "eventMinDistance" BO_ 1804 1000;
BA_ "crcStartValue" BO_ 1804 178;
BA_ "initialValue" SG_ 1804 sig_4_2 2.0;
BA_ "initialValue" SG_ 1804 sig_1_3 -4.0;
BA_ "initialValue" SG_ 1804 sig_21_9 -68.0;
BA_ "initialValue" SG_ 1804 sig_9_7 -2.3377223398316205;
BA_ "initialValue" SG_ 1804 sig_8_1 1.0;
BA_ "initialValue" SG_ 1804 sig_27_4 0.12162277660168382;
BA_ "sendPeriod" BO_ 1530 10000;
BA_ "crcStartValue" BO_ 1530 162;
BA_ "initialValue" SG_ 1530 sig_8_17 -2843.622339831621;
BA_ "initialValue" SG_ 1530 sig_0_8 -0.0012162277660168383;
BA_ "initialValue" SG_ 1530 sig_9_6 76622.77660168378;
BA_ "initialValue" SG_ 1530 sig_44_13 2017.2233983162077;
BA_ "initialValue" SG_ 1530 sig_47_3 -2.0;
BA_ "sendPeriod" BO_ 496 100;
BA_ "crcStartValue" BO_ 496 224;
BA_ "initialValue" SG_ 496 sig_12_11 1.0590000000000008E-4;
BA_ "initialValue" SG_ 496 sig_7_7 -1.837722339831624E-4;
BA_ "initialValue" SG_ 496 sig_8_4 -48377.22339831621;
BA_ "initialValue" SG_ 496 sig_32_8 -94.0;
BA_ "sendPeriod" BO_ 777 25;
BA_ "crcStartValue" BO_ 777 31;
BA_ "sendPeriod" BO_ 1844 50;
BA_ "crcStartValue" BO_ 1844 66;
BA_ "initialValue" SG_ 1844 sig_16_7 0.006377223398316215;
BA_ "initialValue" SG_ 1844 sig_5_8 96.0;
BA_ "initialValue" SG_ 1844 sig_6_8 3.3772233983162074;
BA_ "initialValue" SG_ 1844 sig_30_7 97.0;
BA_ "initialValue" SG_ 1844 sig_45_10 -4.922776601683779E-5;
BA_ "initialValue" SG_ 1844 sig_48_4 1.0;
BA_ "sendPeriod" BO_ 511 1000;
BA_ "crcStartValue" BO_ 511 24;
BA_ "initialValue" SG_ 511 sig_0_8 580.0;
BA_ "sendPeriod" BO_ 616 25;
BA_ "crcStartValue" BO_ 616 132;
BA_ "initialValue" SG_ 616 sig_4_10 0.019922776601683786;
BA_ "initialValue" SG_ 616 sig_14_2 1.0;
BA_ "initialValue" SG_ 616 sig_33_8 8.0;
BA_ "initialValue" SG_ 616 sig_25_8 1.0062277660168384E-4;
BA_ "initialValue" SG_ 616 sig_46_2 1.0;
BA_ "sendPeriod" BO_ 934 5;
BA_ "crcStartValue" BO_ 934 99;
BA_ "initialValue" SG_ 934 sig_2_10 -7.42277660168378E-5;
BA_ "initialValue" SG_ 934 sig_12_4 0.009000000000000003;
BA_ "initialValue" SG_ 934 sig_25_18 35292.0;
BA_ "initialValue" SG_ 934 sig_43_12 -943.0;
BA_ "initialValue" SG_ 934 sig_55_1 1.0;
